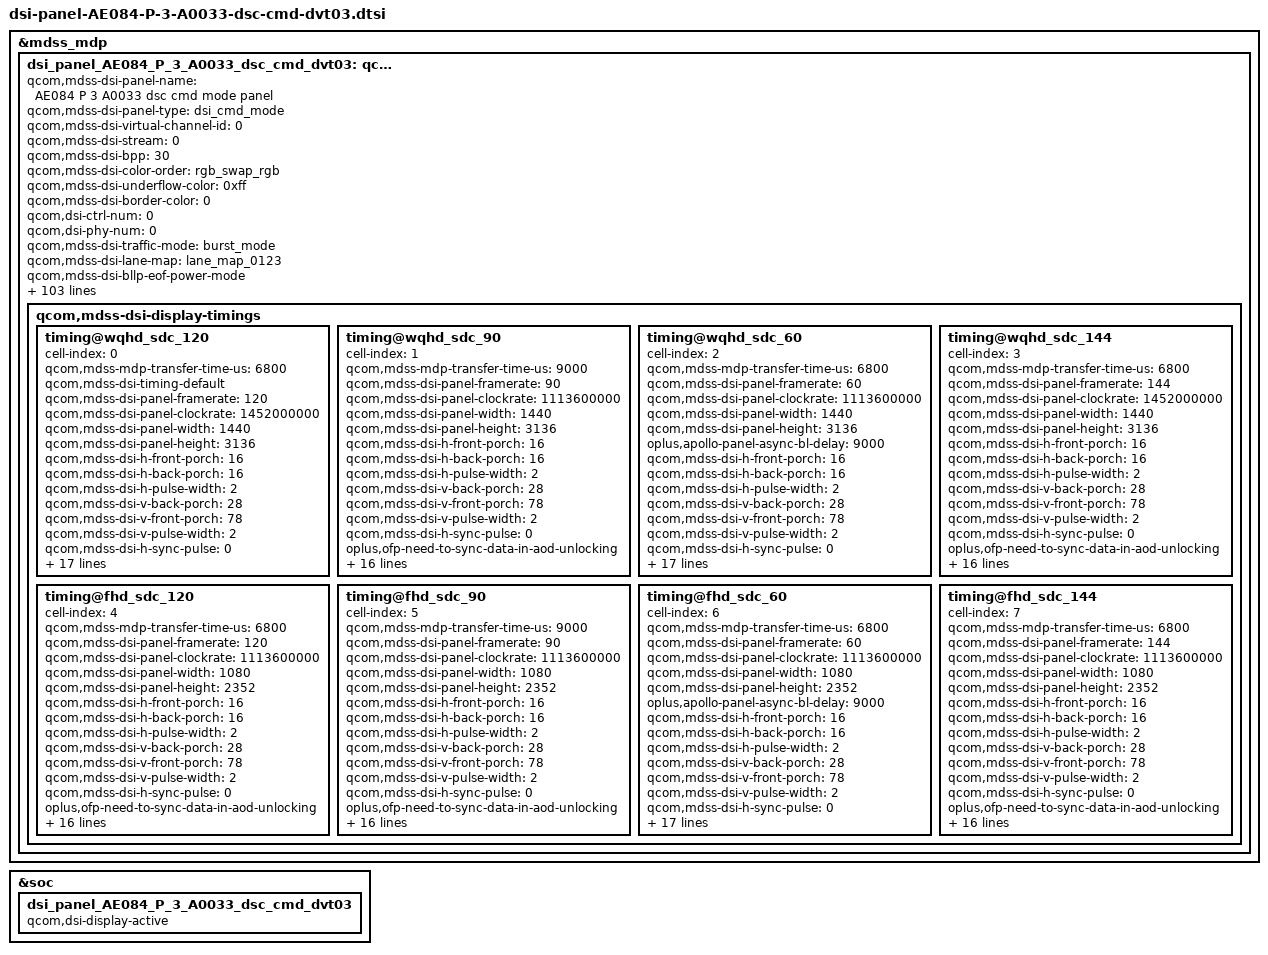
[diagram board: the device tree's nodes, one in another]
&mdss_mdp {
	dsi_panel_AE084_P_3_A0033_dsc_cmd_dvt03: qcom,mdss_dsi_panel_AE084_P_3_A0033_dsc_cmd_dvt03 {
		qcom,mdss-dsi-panel-name = "AE084 P 3 A0033 dsc cmd mode panel";
		qcom,mdss-dsi-panel-type = "dsi_cmd_mode";
		qcom,mdss-dsi-virtual-channel-id = <0>;
		qcom,mdss-dsi-stream = <0>;
		qcom,mdss-dsi-bpp = <30>;
		qcom,mdss-dsi-color-order = "rgb_swap_rgb";
		qcom,mdss-dsi-underflow-color = <0xff>;
		qcom,mdss-dsi-border-color = <0>;
		qcom,dsi-ctrl-num = <0>;
		qcom,dsi-phy-num = <0>;
		qcom,mdss-dsi-traffic-mode = "burst_mode";
		qcom,mdss-dsi-lane-map = "lane_map_0123";
		qcom,mdss-dsi-bllp-eof-power-mode;
		qcom,mdss-dsi-bllp-power-mode;
		qcom,mdss-dsi-lane-0-state;
		qcom,mdss-dsi-lane-1-state;
		qcom,mdss-dsi-lane-2-state;
		qcom,mdss-dsi-lane-3-state;
		qcom,mdss-dsi-dma-trigger = "trigger_sw";
		qcom,mdss-dsi-dma-schedule-line = <1>;
		qcom,mdss-dsi-dma-schedule-window = <10>;
		qcom,mdss-dsi-mdp-trigger = "none";
		qcom,mdss-dsi-reset-sequence = <1 2>, <0 5>, <1 12>;
		qcom,mdss-dsi-te-pin-select = <1>;
		qcom,mdss-dsi-te-dcs-command = <1>;
		qcom,mdss-pan-physical-width-dimension = <71>;
		qcom,mdss-pan-physical-height-dimension = <157>;
		qcom,mdss-dsi-init-delay-us = <1000>;
		qcom,mdss-dsi-te-check-enable;
		qcom,mdss-dsi-te-using-te-pin;
		qcom,mdss-dsi-lp11-init;
		qcom,mdss-dsi-wr-mem-start = <0x2c>;
		qcom,mdss-dsi-wr-mem-continue = <0x3c>;
		qcom,mdss-dsi-panel-jitter = <0x4 0x1>;
		qcom,mdss-bl-high2bit;
		qcom,mdss-dsi-panel-skip-pps-update;
  		/* HDR Setting */
		qcom,mdss-dsi-panel-hdr-enabled;
		qcom,mdss-dsi-panel-hdr-color-primaries = <15635 16450 34000 16000 13250 34500 7500 3000>;
		//update for [MPC15]android.mediapc.cts.PerformanceClassTest#testDisplayHdr pass
		//qcom,mdss-dsi-panel-peak-brightness = <5400000>;
		qcom,mdss-dsi-panel-peak-brightness = <20000000>;
		qcom,mdss-dsi-panel-average-brightness = <2000000>;
		qcom,mdss-dsi-panel-blackness-level = <4000>;

		qcom,mdss-dsi-display-timings {
			//2K
			timing@wqhd_sdc_120 {
				#include "dsi-panel-AE084-P-3-A0033-common.dtsi"
				#include "dsi-panel-AE084-P-3-A0033-common-effect.dtsi"
				cell-index = <0>;
				qcom,mdss-mdp-transfer-time-us = <6800>;
				qcom,mdss-dsi-timing-default;
				qcom,mdss-dsi-panel-framerate = <120>;
				qcom,mdss-dsi-panel-clockrate = <1452000000>;
				qcom,mdss-dsi-panel-width = <1440>;
				qcom,mdss-dsi-panel-height = <3136>;

				qcom,mdss-dsi-h-front-porch = <16>;
				qcom,mdss-dsi-h-back-porch = <16>;
				qcom,mdss-dsi-h-pulse-width = <2>;
				qcom,mdss-dsi-v-back-porch = <28>;
				qcom,mdss-dsi-v-front-porch = <78>;
				qcom,mdss-dsi-v-pulse-width = <2>;
				qcom,mdss-dsi-h-sync-pulse = <0>;

				oplus,ofp-need-to-sync-data-in-aod-unlocking;
				oplus,ofp-aod-off-insert-black-frame = <1>;
				oplus,ofp-aod-off-black-frame-total-time = <42>;
				oplus,ofp-need-to-separate-backlight;
				oplus,ofp-backlight-on-period = <1>;

				qcom,mdss-dsi-timing-switch-command = [
					// OD setting
					39 00 00 40 00 00 47 A9 02 08 E0 00 00 40 02 08 E1 01 02 20 04 02 08 E2 01 02 20 04 02 08 E1 0F 0F 16 02 08 E1 10 10 08 02 08 E2 0F 0F 1C 02 08 E2 10 10 0A 02 08 E1 1D 1E 0D 04 02 08 E2 1D 1E 12 06 02 08 E1 2B 2B 0A 02 08 E2 2B 2B 12
					39 00 00 40 00 00 45 A9 02 08 E1 39 3A 08 04 02 08 E2 39 3A 0A 04 02 08 E1 47 47 06 02 08 E2 47 47 06 02 08 E1 55 55 06 02 08 E2 55 55 06 02 08 E1 63 63 02 02 08 E2 63 63 02 02 08 E1 71 71 02 02 08 E2 71 71 02 02 08 E0 00 00 41
					//DSC setting unlock
					39 00 00 40 00 00 06 F0 55 AA 52 08 00
					39 00 00 40 00 00 02 6F 0D
					39 00 00 40 00 00 02 D8 40
					//DSC SET
					39 00 00 40 00 00 03 90 03 43
					39 00 00 40 00 00 13 91 AB A8 00 10 C2 00 02 68 01 BB 00 0A 06 67 04 C5 10 F0
					39 00 00 40 00 00 13 93 AB A8 00 10 C2 00 02 0E 01 84 00 07 06 67 06 5C 10 F0
					//Resolution binding
					39 00 00 40 00 00 05 2A 00 00 05 9F
					39 00 00 40 00 00 05 2B 00 00 0C 3F
					//DSC setting unlock
					39 00 00 40 00 00 06 F0 55 AA 52 08 00
					39 00 00 40 00 00 02 6F 0D
					39 00 00 40 00 00 02 D8 40
					//scale up off
					39 00 00 40 00 00 02 03 00
					39 00 00 40 00 00 02 8F 00
					//OSC Trim
					39 00 00 40 00 00 50 A9 02 01 C3 02 03 02 87 02 01 C3 08 08 87 02 01 C3 0B 0D 3F 39 4B 02 01 C3 0E 0F 3F 46 02 01 C3 10 10 DD 02 01 C3 11 13 3F 39 4B 02 01 C3 14 16 3F 46 DD 02 01 C3 23 25 3F 31 49 02 01 C3 26 27 3F 57 02 01 C3 28 28 DC 02 01 C3 29 2B 11 00 01
					//DSC setting lock
					39 00 00 40 00 00 06 F0 55 AA 52 08 00
					39 00 00 40 00 00 02 6F 0D
					39 00 00 40 00 00 02 D8 42
					//FPS setting 120Hz
					39 00 00 00 01 00 8F A9 01 00 2F 00 00 01 02 09 BD 00 00 05 02 08 B7 08 0F 00 C8 00 C8 02 58 02 58 02 08 B7 10 1F 03 E8 03 E8 03 E8 03 E8 05 DC 05 DC 07 D0 07 D0 02 08 B7 20 27 09 C4 09 C4 08 FC 08 FC 02 08 B7 28 2D 08 00 08 00 08 00 01 00 A2 00 20 07 02 01 DD 02 03 00 00 00 00 00 00 00 00 02 04 B5 02 03 00 03 00 00 00 00 00 00 01 00 9D 00 00 AA 01 00 8D 02 02 01 01 00 A3 00 0F 81 00 00 00 00 02 09 BD 00 00 04 00 00 00 00 00 01 00 A3 10 11 00 00
					39 00 00 00 00 00 06 F0 55 AA 52 08 FF
				];
				qcom,mdss-dsi-on-command = [
					//GPIO setting
					39 00 00 40 00 00 06 F0 55 AA 52 08 00
					39 00 00 40 00 00 05 BE 49 47 47 4A
					//APL BLK Setting
					39 00 00 40 00 00 06 F0 55 AA 52 08 00
					39 00 00 40 00 00 02 6F 78
					39 00 00 40 00 00 18 B0 11 00 2A 00 C2 01 DA 03 7C 05 B1 08 80 0B EE 0F FF 05 55 05 56 05 55
					//APL_BLK_R_NUM,APL_BLK_G_NUM,APL_BLK_B_NUM
					39 00 00 40 00 00 02 6F 6F
					39 00 00 40 00 00 07 B0 02 D0 05 A0 02 D0
					//Data Scale Ratio
					39 00 00 40 00 00 06 F0 55 AA 52 08 08
					39 00 00 40 00 00 17 C1 8E 33 EE 33 33 EE 33 33 EE 33 33 EE 33 33 BE 33 AC 9B AC 0D 0F FF
					39 00 00 40 00 00 02 6F 23
					39 00 00 40 00 00 15 C1 0E 33 EE 33 33 EE 33 33 EE 33 33 EE 33 33 BE 33 AC 9B AC 0D
					39 00 00 40 00 00 02 6F 37
					39 00 00 40 00 00 15 C1 0F FF FF FF FF FF FF FF FF FF FF FF FF FF DF FF 27 AD 27 33
					39 00 00 40 00 00 02 6F 4B
					39 00 00 40 00 00 15 C1 0E 33 EE 33 33 EE 33 33 EE 33 33 EE 33 33 BE 33 AC 9B AC 0D
					39 00 00 40 00 00 02 6F 5F
					39 00 00 40 00 00 15 C1 0F FF FF FF FF FF FF FF FF FF FF FF FF FF FF FF FF FF FF FF
					39 00 00 40 00 00 02 6F 73
					39 00 00 40 00 00 15 C1 0E 33 EE 33 33 EE 33 33 EE 33 33 EE 33 33 BE 33 AC 9B AC 0D
					//DS_DBV_TH
					39 00 00 40 00 00 11 BA 00 01 00 8A 00 8A 01 3C 01 3C 01 9D 01 9D 02 79
					39 00 00 40 00 00 02 6F 10
					39 00 00 40 00 00 11 BA 02 79 03 7D 03 7D 04 93 04 93 06 98 06 98 0A E2
					39 00 00 40 00 00 02 6F 20
					39 00 00 40 00 00 0D BA 0A E2 0D BB 0D BB 0F FE 0F FE 0F FF
					//APL_L/APL_H
					39 00 00 40 00 00 02 6F 20
					39 00 00 40 00 00 04 C1 0F 29 FF
					//HBM_LV0/1/2
					39 00 00 40 00 00 02 6F 1D
					39 00 00 40 00 00 04 C1 00 80 FF
					39 00 00 40 00 00 05 FF AA 55 A5 80
					//OSC Charge up 4uA
					39 00 00 40 00 00 02 6F 07
					39 00 00 40 00 00 02 F8 4D
					39 00 00 40 00 00 02 6F 23
					39 00 00 40 00 00 02 F8 4D
					//mtp_vgh_setting
					39 00 00 40 00 00 02 6F 04
					39 00 00 40 00 00 02 F2 1D
					//power on/off sequence
					39 00 00 40 00 00 02 6F 0A
					39 00 00 40 00 00 06 F6 70 70 70 70 70
					// stop_hclk_fskip & stop_hclk_vfp = 1
					39 00 00 40 00 00 05 FF AA 55 A5 81
					39 00 00 40 00 00 02 6F 0E
					39 00 00 40 00 00 02 F5 2B
					//bois clk,idle vfp clk off
					39 00 00 40 00 00 02 6F 0F
					39 00 00 40 00 00 02 F5 22
					// porch source setting
					39 00 00 40 00 00 02 6F 05
					39 00 00 40 00 00 03 FE 3C 3C
					//mipi timing optimize
					39 00 00 40 00 00 05 FF AA 55 A5 82
					39 00 00 40 00 00 02 6F 12
					39 00 00 40 00 00 03 F2 23 25
					//source status @ mtp status = hi-z
					39 00 00 40 00 00 06 F0 55 AA 52 08 00
					39 00 00 40 00 00 02 6F 04
					39 00 00 40 00 00 02 C2 32
					//Blue spot optimization
					39 00 00 40 00 00 06 F0 55 AA 52 08 00
					39 00 00 40 00 00 02 6F 31
					39 00 00 40 00 00 04 C0 00 22 00
					39 00 00 40 00 00 06 F0 55 AA 52 08 00
					39 00 00 40 00 00 02 6F 39
					39 00 00 40 00 00 04 C0 11 33 00
					//scaling up setting
					39 00 00 40 00 00 02 6F 0D
					39 00 00 40 00 00 02 D8 40
					39 00 00 40 00 00 02 C0 44
					//goa status @ mtp status = toggle
					39 00 00 40 00 00 06 F0 55 AA 52 08 01
					39 00 00 40 00 00 02 6F 08
					39 00 00 40 00 00 02 CA 00
					//keep command mode
					39 00 00 40 00 00 05 FF AA 55 A5 00
					39 00 00 40 00 00 06 F0 55 AA 52 00 00
					39 00 00 40 00 00 02 6F 02
					39 00 00 40 00 00 02 17 12
					39 00 00 40 00 00 02 35 08
					//BC Dimming OFF
					39 00 00 40 00 00 02 53 20
					//H_res = 1440 , V_res = 3136
					39 00 00 40 00 00 05 2a 00 00 05 9f
					39 00 00 40 00 00 05 2b 00 00 0C 3f
					//normal gma
					39 00 00 40 00 00 02 26 00
					//normal dbv
					39 00 00 40 00 00 03 51 00 00
					//idle dbv
					39 00 00 40 00 00 02 6F 04
					39 00 00 40 00 00 03 51 0D BB
					//LFCC LUT Table Sel
					39 00 00 40 00 00 02 68 00
					//md1,dpc temperature
					39 00 00 40 00 00 03 81 01 19
					//DSC setting unlock
					39 00 00 40 00 00 07 A9 02 00 D8 0D 0D 40
					//DSC SET
					39 00 00 40 00 00 03 90 03 43
					39 00 00 40 00 00 13 91 AB A8 00 10 C2 00 02 68 01 BB 00 0A 06 67 04 C5 10 F0
					39 00 00 00 00 00 13 93 AB A8 00 10 C2 00 02 0E 01 84 00 07 06 67 06 5C 10 F0
					//vdc & peak luminance
					39 00 00 40 00 00 03 5F 00 C0
					39 00 00 40 00 00 02 6F 07
					39 00 00 40 00 00 02 51 00
					//1nit rolling horizontal stripes
					39 00 00 40 00 00 06 F0 55 AA 52 08 00
					39 00 00 40 00 00 02 6F 62
					39 00 00 40 00 00 02 D5 0F
					39 00 00 40 00 00 02 6F 68
					39 00 00 40 00 00 02 D5 10
					//RND OFF
					39 00 00 40 00 00 06 F0 55 AA 52 08 07
					39 00 00 40 00 00 02 C0 06

					//OSC Trim
					39 00 00 40 00 00 06 F0 55 AA 52 08 01
					39 00 00 40 00 00 36 C3 99 29 02 87 19 00 29 00 87 19 00 3F 39 4B 3F 46 DD 3F 39 4B 3F 46 DD 3F 51 FE 3F 25 A9 3F 51 FE 3F 25 A9 3F 38 FC 3F 2C A8 11 00 00 00 00 00 77 00 AA 02 AA 02
					15 00 00 40 00 00 02 6F 04
					15 00 00 40 00 00 02 C3 19
					15 00 00 40 00 00 02 6F 09
					15 00 00 40 00 00 02 C3 19

					// OD setting
					39 00 00 40 00 00 06 F0 55 AA 52 08 08
					39 00 00 40 00 00 05 E0 41 01 01 01
					39 00 00 40 00 00 02 6F 06
					39 00 00 40 00 00 0E E0 80 00 21 32 43 54 65 76 87 98 99 99 99
					39 00 00 40 00 00 0F E1 03 20 04 0D 0E 0F 0F 10 12 14 14 17 1C 20
					39 00 00 40 00 00 0F E2 03 20 04 0A 0C 0E 10 12 17 1A 1E 1F 20 21
					39 00 00 40 00 00 0F E3 00 00 00 00 00 00 00 00 00 00 00 00 00 00
					39 00 00 40 00 00 02 6F 0E
					39 00 00 40 00 00 0F E1 03 16 08 0A 0B 0B 0C 0D 0E 0E 12 14 17 20
					39 00 00 40 00 00 02 6F 0E
					39 00 00 40 00 00 0F E2 03 1C 0A 0F 10 10 11 12 13 13 14 15 17 19
					39 00 00 40 00 00 02 6F 0E
					39 00 00 40 00 00 0F E3 00 00 00 00 00 00 00 00 00 00 00 00 00 00
					39 00 00 40 00 00 02 6F 1C
					39 00 00 40 00 00 0F E1 02 0D 04 0A 0A 0A 0A 0A 0A 0A 0B 0B 0D 0F
					39 00 00 40 00 00 02 6F 1C
					39 00 00 40 00 00 0F E2 02 12 06 06 06 07 08 08 08 08 08 0A 0C 0D
					39 00 00 40 00 00 02 6F 1C
					39 00 00 40 00 00 0F E3 00 00 00 04 04 04 04 04 07 07 08 08 0C 0F
					39 00 00 40 00 00 02 6F 2A
					39 00 00 40 00 00 0F E1 01 0A 04 05 05 06 07 08 08 0A 0B 0B 0E 13
					39 00 00 40 00 00 02 6F 2A
					39 00 00 40 00 00 0F E2 02 12 04 08 08 08 08 08 08 08 0A 0B 0D 11
					39 00 00 40 00 00 02 6F 2A
					39 00 00 40 00 00 0F E3 00 00 00 03 03 03 03 03  03 07 09 0B 0D 12
					39 00 00 40 00 00 02 6F 38
					39 00 00 40 00 00 0F E1 01 08 04 05 05 05 05 05 06 09 0A 0B 0D 11
					39 00 00 40 00 00 02 6F 38
					39 00 00 40 00 00 0F E2 01 0A 04 05 05 05 06 06 06 07 09 0B 0D 10
					39 00 00 40 00 00 02 6F 38
					39 00 00 40 00 00 0F E3 00 00 00 04 04 04 04 04 05 07 08 0A 0D 0F
					39 00 00 40 00 00 02 6F 46
					39 00 00 40 00 00 0F E1 01 06 03 05 05 05 05 05 06 08 09 0B 0C 0F
					39 00 00 40 00 00 02 6F 46
					39 00 00 40 00 00 0F E2 01 06 03 04 04 04 04 04 06 08 09 0A 0C 0F
					39 00 00 40 00 00 02 6F 46
					39 00 00 40 00 00 0F E3 00 00 00 03 03 03 03 03 06 08 09 0A 0C 10
					39 00 00 40 00 00 02 6F 54
					39 00 00 40 00 00 0F E1 01 06 03 04 04 04 04 04 06 08 09 0A 0B 0F
					39 00 00 40 00 00 02 6F 54
					39 00 00 40 00 00 0F E2 01 06 03 04 04 04 04 04 06 07 09 0A 0B 0E
					39 00 00 40 00 00 02 6F 54
					39 00 00 40 00 00 0F E3 00 00 00 02 02 03 03 04 05 07 09 0C 0E 12
					39 00 00 40 00 00 02 6F 62
					39 00 00 40 00 00 0F E1 01 02 02 03 03 04 04 04 06 07 08 0A 0C 0F
					39 00 00 40 00 00 02 6F 62
					39 00 00 40 00 00 0F E2 01 02 02 02 03 03 03 04 05 07 08 09 0A 0E
					39 00 00 40 00 00 02 6F 62
					39 00 00 40 00 00 0F E3 00 00 00 02 02 03 03 04 06 08 0A 0D 0E 12
					39 00 00 40 00 00 02 6F 70
					39 00 00 40 00 00 0F E1 01 02 02 02 03 03 03 04 05 07 09 0C 0D 11
					39 00 00 40 00 00 02 6F 70
					39 00 00 40 00 00 0F E2 01 02 02 02 03 03 03 04 05 07 09 0B 0C 0F
					39 00 00 40 00 00 02 6F 70
					39 00 00 40 00 00 0F E3 00 00 00 02 03 03 03 04 06 08 0B 0C 0C 0F

					//add uir config
					39 00 00 40 00 00 06 F0 55 AA 52 08 00
					15 00 00 40 00 00 02 6F 78
					39 00 00 40 00 00 18 B0 17 00 2A 00 C2 01 DA 03 7C 05 B1 08 80 0B EE 0F FF 05 55 05 56 05 55
					//APL_BLK_R_NUM,APL_BLK_G_NUM,APL_BLK_B_NUM
					15 00 00 40 00 00 02 6F 6F
					39 00 00 40 00 00 07 B0 02 D0 05 A0 02 D0
					//Data Scale Ratio
					39 00 00 40 00 00 06 F0 55 AA 52 08 08
					//DS_LV0_APL0
					39 00 00 40 00 00 17 C1 8E 33 EE 33 33 EE 33 33 EE 33 33 EE 33 33 BE 33 AC 9B AC 0D 0F FF
					//HBM_LV
					15 00 00 40 00 00 02 6F 1D
					39 00 00 40 00 00 03 C1 00 FF
					//APL_L/APL_H
					15 00 00 40 00 00 02 6F 20
					39 00 00 40 00 00 04 C1 0F 29 FF
					//DS_LV0_APL1
					15 00 00 40 00 00 02 6F 23
					39 00 00 40 00 00 15 C1 0E 33 EE 33 33 EE 33 33 EE 33 33 EE 33 33 BE 33 AC 9B AC 0D
					//DS_Lv1_Apl0
					15 00 00 40 00 00 02 6F 37
					39 00 00 40 00 00 15 C1 0F FF FF FF FF FF FF FF FF FF FF FF FF FF DF FF 27 AD 27 33
					//DS_Lv1_Apl1
					15 00 00 40 00 00 02 6F 4B
					39 00 00 40 00 00 15 C1 0E 33 EE 33 33 EE 33 33 EE 33 33 EE 33 33 BE 33 AC 9B AC 0D
					//DS_LV2_APL0
					15 00 00 40 00 00 02 6F 5F
					39 00 00 40 00 00 15 C1 0F FF FF FF FF FF FF FF FF FF FF FF FF FF FF FF FF FF FF FF
					//DS_LV2_APL1
					15 00 00 40 00 00 02 6F 73
					39 00 00 40 00 00 15 C1 0E 33 EE 33 33 EE 33 33 EE 33 33 EE 33 33 BE 33 AC 9B AC 0D
					//DS_DBV_TH
					39 00 00 40 00 00 11 BA 00 01 00 8A 00 8A 01 3C 01 3C 01 9D 01 9D 02 79
					15 00 00 40 00 00 02 6F 10
					39 00 00 40 00 00 11 BA 02 79 03 7D 03 7D 04 93 04 93 06 98 06 98 0A E2
					15 00 00 40 00 00 02 6F 20
					39 00 00 40 00 00 0D BA 0A E2 0D BB 0D BB 0F FE 0F FE 0F FF
					//GIR1.0
					15 00 00 40 00 00 02 6F 07
					15 00 00 00 00 00 02 51 00

					//Sleep out
					15 00 00 00 78 00 02 11 00
					//Display out
					15 00 00 00 00 00 02 29 00
					//scale up off
					39 00 00 40 00 00 05 2A 00 00 05 9F
					39 00 00 40 00 00 05 2B 00 00 0C 3F
					39 00 00 40 00 00 02 03 00
					39 00 00 40 00 00 02 8F 00
					//OSC Trim
					39 00 00 40 00 00 50 A9 02 01 C3 02 03 02 87 02 01 C3 08 08 87 02 01 C3 0B 0D 3F 39 4B 02 01 C3 0E 0F 3F 46 02 01 C3 10 10 DD 02 01 C3 11 13 3F 39 4B 02 01 C3 14 16 3F 46 DD 02 01 C3 23 25 3F 31 49 02 01 C3 26 27 3F 57 02 01 C3 28 28 DC 02 01 C3 29 2B 11 00 01
					//DSC setting lock
					39 00 00 40 00 00 07 A9 02 00 D8 0D 0D 42
					//FPS setting 120Hz
					39 00 00 00 01 00 8F A9 01 00 2F 00 00 01 02 09 BD 00 00 05 02 08 B7 08 0F 00 C8 00 C8 02 58 02 58 02 08 B7 10 1F 03 E8 03 E8 03 E8 03 E8 05 DC 05 DC 07 D0 07 D0 02 08 B7 20 27 09 C4 09 C4 08 FC 08 FC 02 08 B7 28 2D 08 00 08 00 08 00 01 00 A2 00 20 07 02 01 DD 02 03 00 00 00 00 00 00 00 00 02 04 B5 02 03 00 03 00 00 00 00 00 00 01 00 9D 00 00 AA 01 00 8D 02 02 01 01 00 A3 00 0F 81 00 00 00 00 02 09 BD 00 00 04 00 00 00 00 00 01 00 A3 10 11 00 00
				];

				qcom,lm-split = <720 720>;
				qcom,mdss-dsc-slice-height = <16>;
				qcom,mdss-dsc-slice-width = <720>;
			};
			timing@wqhd_sdc_90 {
				#include "dsi-panel-AE084-P-3-A0033-common.dtsi"
				#include "dsi-panel-AE084-P-3-A0033-common-effect.dtsi"
				cell-index = <1>;
				qcom,mdss-mdp-transfer-time-us = <9000>;
				qcom,mdss-dsi-panel-framerate = <90>;
				qcom,mdss-dsi-panel-clockrate = <1113600000>;
				qcom,mdss-dsi-panel-width = <1440>;
				qcom,mdss-dsi-panel-height = <3136>;

				qcom,mdss-dsi-h-front-porch = <16>;
				qcom,mdss-dsi-h-back-porch = <16>;
				qcom,mdss-dsi-h-pulse-width = <2>;
				qcom,mdss-dsi-v-back-porch = <28>;
				qcom,mdss-dsi-v-front-porch = <78>;
				qcom,mdss-dsi-v-pulse-width = <2>;
				qcom,mdss-dsi-h-sync-pulse = <0>;

				oplus,ofp-need-to-sync-data-in-aod-unlocking;
				oplus,ofp-aod-off-insert-black-frame = <1>;
				oplus,ofp-aod-off-black-frame-total-time = <42>;
				oplus,ofp-need-to-separate-backlight;
				oplus,ofp-backlight-on-period = <1>;

				qcom,mdss-dsi-timing-switch-command = [
					// OD setting
					39 00 00 40 00 00 47 A9 02 08 E0 00 00 40 02 08 E1 01 02 18 08 02 08 E2 01 02 1A 08 02 08 E1 0F 0F 1A 02 08 E1 10 10 08 02 08 E2 0F 0F 1A 02 08 E2 10 10 0B 02 08 E1 1D 1E 08 05 02 08 E2 1D 1E 0A 06 02 08 E1 2B 2B 09 02 08 E2 2B 2B 0B
					39 00 00 40 00 00 45 A9 02 08 E1 39 3A 04 04 02 08 E2 39 3A 04 04 02 08 E1 47 47 03 02 08 E2 47 47 03 02 08 E1 55 55 03 02 08 E2 55 55 03 02 08 E1 63 63 01 02 08 E2 63 63 01 02 08 E1 71 71 01 02 08 E2 71 71 01 02 08 E0 00 00 41
					//DSC setting unlock
					39 00 00 40 00 00 06 F0 55 AA 52 08 00
					39 00 00 40 00 00 02 6F 0D
					39 00 00 40 00 00 02 D8 40
					//DSC SET
					39 00 00 40 00 00 03 90 03 43
					39 00 00 40 00 00 13 91 AB A8 00 10 C2 00 02 68 01 BB 00 0A 06 67 04 C5 10 F0
					39 00 00 40 00 00 13 93 AB A8 00 10 C2 00 02 0E 01 84 00 07 06 67 06 5C 10 F0
					//Resolution binding
					39 00 00 40 00 00 05 2A 00 00 05 9F
					39 00 00 40 00 00 05 2B 00 00 0C 3F
					//DSC setting unlock
					39 00 00 40 00 00 06 F0 55 AA 52 08 00
					39 00 00 40 00 00 02 6F 0D
					39 00 00 40 00 00 02 D8 40
					//scale up off
					39 00 00 40 00 00 02 03 00
					39 00 00 40 00 00 02 8F 00
					//OSC Trim
					39 00 00 40 00 00 50 A9 02 01 C3 02 03 02 87 02 01 C3 08 08 87 02 01 C3 0B 0D 3F 39 4B 02 01 C3 0E 0F 3F 46 02 01 C3 10 10 DD 02 01 C3 11 13 3F 39 4B 02 01 C3 14 16 3F 46 DD 02 01 C3 23 25 3F 38 FC 02 01 C3 26 27 3F 2C 02 01 C3 28 28 A8 02 01 C3 29 2B 11 00 00
					//DSC setting lock
					39 00 00 40 00 00 06 F0 55 AA 52 08 00
					39 00 00 40 00 00 02 6F 0D
					39 00 00 40 00 00 02 D8 42
					//FPS setting 90Hz
					39 00 00 00 01 00 8F A9 01 00 2F 00 00 02 02 09 BD 00 00 05 02 08 B7 08 0F 00 C8 00 C8 02 58 02 58 02 08 B7 10 1F 03 E8 03 E8 03 E8 03 E8 05 DC 05 DC 07 D0 07 D0 02 08 B7 20 27 09 C4 09 C4 08 FC 08 FC 02 08 B7 28 2D 08 00 08 00 08 00 01 00 A2 00 20 07 02 01 DD 02 03 00 00 00 00 00 00 00 00 02 04 B5 02 03 00 09 00 00 00 00 00 00 01 00 9D 00 00 AA 01 00 8D 02 02 01 01 00 A3 00 0F 81 00 00 00 00 02 09 BD 00 00 04 00 00 00 00 00 01 00 A3 10 11 00 00
					39 00 00 00 00 00 06 F0 55 AA 52 08 FF
				];
				qcom,mdss-dsi-on-command = [
					//GPIO setting
					39 00 00 40 00 00 06 F0 55 AA 52 08 00
					39 00 00 40 00 00 05 BE 49 47 47 4A
					//APL BLK Setting
					39 00 00 40 00 00 06 F0 55 AA 52 08 00
					39 00 00 40 00 00 02 6F 78
					39 00 00 40 00 00 18 B0 11 00 2A 00 C2 01 DA 03 7C 05 B1 08 80 0B EE 0F FF 05 55 05 56 05 55
					//APL_BLK_R_NUM,APL_BLK_G_NUM,APL_BLK_B_NUM
					39 00 00 40 00 00 02 6F 6F
					39 00 00 40 00 00 07 B0 02 D0 05 A0 02 D0
					//Data Scale Ratio
					39 00 00 40 00 00 06 F0 55 AA 52 08 08
					39 00 00 40 00 00 17 C1 8E 33 EE 33 33 EE 33 33 EE 33 33 EE 33 33 BE 33 AC 9B AC 0D 0F FF
					39 00 00 40 00 00 02 6F 23
					39 00 00 40 00 00 15 C1 0E 33 EE 33 33 EE 33 33 EE 33 33 EE 33 33 BE 33 AC 9B AC 0D
					39 00 00 40 00 00 02 6F 37
					39 00 00 40 00 00 15 C1 0F FF FF FF FF FF FF FF FF FF FF FF FF FF DF FF 27 AD 27 33
					39 00 00 40 00 00 02 6F 4B
					39 00 00 40 00 00 15 C1 0E 33 EE 33 33 EE 33 33 EE 33 33 EE 33 33 BE 33 AC 9B AC 0D
					39 00 00 40 00 00 02 6F 5F
					39 00 00 40 00 00 15 C1 0F FF FF FF FF FF FF FF FF FF FF FF FF FF FF FF FF FF FF FF
					39 00 00 40 00 00 02 6F 73
					39 00 00 40 00 00 15 C1 0E 33 EE 33 33 EE 33 33 EE 33 33 EE 33 33 BE 33 AC 9B AC 0D
					//DS_DBV_TH
					39 00 00 40 00 00 11 BA 00 01 00 8A 00 8A 01 3C 01 3C 01 9D 01 9D 02 79
					39 00 00 40 00 00 02 6F 10
					39 00 00 40 00 00 11 BA 02 79 03 7D 03 7D 04 93 04 93 06 98 06 98 0A E2
					39 00 00 40 00 00 02 6F 20
					39 00 00 40 00 00 0D BA 0A E2 0D BB 0D BB 0F FE 0F FE 0F FF
					//APL_L/APL_H
					39 00 00 40 00 00 02 6F 20
					39 00 00 40 00 00 04 C1 0F 29 FF
					//HBM_LV0/1/2
					39 00 00 40 00 00 02 6F 1D
					39 00 00 40 00 00 04 C1 00 80 FF
					39 00 00 40 00 00 05 FF AA 55 A5 80
					//OSC Charge up 4uA
					39 00 00 40 00 00 02 6F 07
					39 00 00 40 00 00 02 F8 4D
					39 00 00 40 00 00 02 6F 23
					39 00 00 40 00 00 02 F8 4D
					//mtp_vgh_setting
					39 00 00 40 00 00 02 6F 04
					39 00 00 40 00 00 02 F2 1D
					//power on/off sequence
					39 00 00 40 00 00 02 6F 0A
					39 00 00 40 00 00 06 F6 70 70 70 70 70
					// stop_hclk_fskip & stop_hclk_vfp = 1
					39 00 00 40 00 00 05 FF AA 55 A5 81
					39 00 00 40 00 00 02 6F 0E
					39 00 00 40 00 00 02 F5 2B
					//bois clk,idle vfp clk off
					39 00 00 40 00 00 02 6F 0F
					39 00 00 40 00 00 02 F5 22
					// porch source setting
					39 00 00 40 00 00 02 6F 05
					39 00 00 40 00 00 03 FE 3C 3C
					//mipi timing optimize
					39 00 00 40 00 00 05 FF AA 55 A5 82
					39 00 00 40 00 00 02 6F 12
					39 00 00 40 00 00 03 F2 23 25
					//source status @ mtp status = hi-z
					39 00 00 40 00 00 06 F0 55 AA 52 08 00
					39 00 00 40 00 00 02 6F 04
					39 00 00 40 00 00 02 C2 32
					//Blue spot optimization
					39 00 00 40 00 00 06 F0 55 AA 52 08 00
					39 00 00 40 00 00 02 6F 31
					39 00 00 40 00 00 04 C0 00 22 00
					39 00 00 40 00 00 06 F0 55 AA 52 08 00
					39 00 00 40 00 00 02 6F 39
					39 00 00 40 00 00 04 C0 11 33 00
					//scaling up setting
					39 00 00 40 00 00 02 6F 0D
					39 00 00 40 00 00 02 D8 40
					39 00 00 40 00 00 02 C0 44
					//goa status @ mtp status = toggle
					39 00 00 40 00 00 06 F0 55 AA 52 08 01
					39 00 00 40 00 00 02 6F 08
					39 00 00 40 00 00 02 CA 00
					//keep command mode
					39 00 00 40 00 00 05 FF AA 55 A5 00
					39 00 00 40 00 00 06 F0 55 AA 52 00 00
					39 00 00 40 00 00 02 6F 02
					39 00 00 40 00 00 02 17 12
					39 00 00 40 00 00 02 35 08
					//BC Dimming OFF
					39 00 00 40 00 00 02 53 20
					//H_res = 1440 , V_res = 3136
					39 00 00 40 00 00 05 2a 00 00 05 9f
					39 00 00 40 00 00 05 2b 00 00 0C 3f
					//normal gma
					39 00 00 40 00 00 02 26 00
					//normal dbv
					39 00 00 40 00 00 03 51 00 00
					//idle dbv
					39 00 00 40 00 00 02 6F 04
					39 00 00 40 00 00 03 51 0D BB
					//LFCC LUT Table Sel
					39 00 00 40 00 00 02 68 00
					//md1,dpc temperature
					39 00 00 40 00 00 03 81 01 19
					//DSC setting unlock
					39 00 00 40 00 00 07 A9 02 00 D8 0D 0D 40
					//DSC SET
					39 00 00 40 00 00 03 90 03 43
					39 00 00 40 00 00 13 91 AB A8 00 10 C2 00 02 68 01 BB 00 0A 06 67 04 C5 10 F0
					39 00 00 00 00 00 13 93 AB A8 00 10 C2 00 02 0E 01 84 00 07 06 67 06 5C 10 F0
					//vdc & peak luminance
					39 00 00 40 00 00 03 5F 00 C0
					39 00 00 40 00 00 02 6F 07
					39 00 00 40 00 00 02 51 00
					//1nit rolling horizontal stripes
					39 00 00 40 00 00 06 F0 55 AA 52 08 00
					39 00 00 40 00 00 02 6F 62
					39 00 00 40 00 00 02 D5 0F
					39 00 00 40 00 00 02 6F 68
					39 00 00 40 00 00 02 D5 10
					//RND OFF
					39 00 00 40 00 00 06 F0 55 AA 52 08 07
					39 00 00 40 00 00 02 C0 06

					//OSC Trim
					39 00 00 40 00 00 06 F0 55 AA 52 08 01
					39 00 00 40 00 00 36 C3 99 29 02 87 19 00 29 00 87 19 00 3F 39 4B 3F 46 DD 3F 39 4B 3F 46 DD 3F 51 FE 3F 25 A9 3F 51 FE 3F 25 A9 3F 38 FC 3F 2C A8 11 00 00 00 00 00 77 00 AA 02 AA 02
					15 00 00 40 00 00 02 6F 04
					15 00 00 40 00 00 02 C3 19
					15 00 00 40 00 00 02 6F 09
					15 00 00 40 00 00 02 C3 19

					// OD setting
					39 00 00 40 00 00 06 F0 55 AA 52 08 08
					39 00 00 40 00 00 05 E0 41 01 01 01
					39 00 00 40 00 00 02 6F 06
					39 00 00 40 00 00 0E E0 80 00 21 32 43 54 65 76 87 98 99 99 99
					39 00 00 40 00 00 0F E1 03 18 08 0D 0E 0F 0F 10 12 14 14 17 1C 20
					39 00 00 40 00 00 0F E2 03 1A 08 0A 0C 0E 10 12 17 1A 1E 1F 20 21
					39 00 00 40 00 00 0F E3 00 00 00 00 00 00 00 00 00 00 00 00 00 00
					39 00 00 40 00 00 02 6F 0E
					39 00 00 40 00 00 0F E1 03 18 08 0A 0B 0B 0C 0D 0E 0E 12 14 17 20
					39 00 00 40 00 00 02 6F 0E
					39 00 00 40 00 00 0F E2 03 1A 0B 0F 10 10 11 12 13 13 14 15 17 19
					39 00 00 40 00 00 02 6F 0E
					39 00 00 40 00 00 0F E3 00 00 00 00 00 00 00 00 00 00 00 00 00 00
					39 00 00 40 00 00 02 6F 1C
					39 00 00 40 00 00 0F E1 02 08 05 0A 0A 0A 0A 0A 0A 0A 0B 0B 0D 0F
					39 00 00 40 00 00 02 6F 1C
					39 00 00 40 00 00 0F E2 02 0A 06 06 06 07 08 08 08 08 08 0A 0C 0D
					39 00 00 40 00 00 02 6F 1C
					39 00 00 40 00 00 0F E3 00 00 00 04 04 04 04 04 07 07 08 08 0C 0F
					39 00 00 40 00 00 02 6F 2A
					39 00 00 40 00 00 0F E1 01 09 04 05 05 06 07 08 08 0A 0B 0B 0E 13
					39 00 00 40 00 00 02 6F 2A
					39 00 00 40 00 00 0F E2 02 0B 04 08 08 08 08 08 08 08 0A 0B 0D 11
					39 00 00 40 00 00 02 6F 2A
					39 00 00 40 00 00 0F E3 00 00 00 03 03 03 03 03  03 07 09 0B 0D 12
					39 00 00 40 00 00 02 6F 38
					39 00 00 40 00 00 0F E1 01 04 04 05 05 05 05 05 06 09 0A 0B 0D 11
					39 00 00 40 00 00 02 6F 38
					39 00 00 40 00 00 0F E2 01 04 04 05 05 05 06 06 06 07 09 0B 0D 10
					39 00 00 40 00 00 02 6F 38
					39 00 00 40 00 00 0F E3 00 00 00 04 04 04 04 04 05 07 08 0A 0D 0F
					39 00 00 40 00 00 02 6F 46
					39 00 00 40 00 00 0F E1 01 03 03 05 05 05 05 05 06 08 09 0B 0C 0F
					39 00 00 40 00 00 02 6F 46
					39 00 00 40 00 00 0F E2 01 03 03 04 04 04 04 04 06 08 09 0A 0C 0F
					39 00 00 40 00 00 02 6F 46
					39 00 00 40 00 00 0F E3 00 00 00 03 03 03 03 03 06 08 09 0A 0C 10
					39 00 00 40 00 00 02 6F 54
					39 00 00 40 00 00 0F E1 01 03 03 04 04 04 04 04 06 08 09 0A 0B 0F
					39 00 00 40 00 00 02 6F 54
					39 00 00 40 00 00 0F E2 01 03 03 04 04 04 04 04 06 07 09 0A 0B 0E
					39 00 00 40 00 00 02 6F 54
					39 00 00 40 00 00 0F E3 00 00 00 02 02 03 03 04 05 07 09 0C 0E 12
					39 00 00 40 00 00 02 6F 62
					39 00 00 40 00 00 0F E1 01 01 02 03 03 04 04 04 06 07 08 0A 0C 0F
					39 00 00 40 00 00 02 6F 62
					39 00 00 40 00 00 0F E2 01 01 02 02 03 03 03 04 05 07 08 09 0A 0E
					39 00 00 40 00 00 02 6F 62
					39 00 00 40 00 00 0F E3 00 00 00 02 02 03 03 04 06 08 0A 0D 0E 12
					39 00 00 40 00 00 02 6F 70
					39 00 00 40 00 00 0F E1 01 01 02 02 03 03 03 04 05 07 09 0C 0D 11
					39 00 00 40 00 00 02 6F 70
					39 00 00 40 00 00 0F E2 01 01 02 02 03 03 03 04 05 07 09 0B 0C 0F
					39 00 00 40 00 00 02 6F 70
					39 00 00 40 00 00 0F E3 00 00 00 02 03 03 03 04 06 08 0B 0C 0C 0F

					//add uir config
					39 00 00 40 00 00 06 F0 55 AA 52 08 00
					15 00 00 40 00 00 02 6F 78
					39 00 00 40 00 00 18 B0 17 00 2A 00 C2 01 DA 03 7C 05 B1 08 80 0B EE 0F FF 05 55 05 56 05 55
					//APL_BLK_R_NUM,APL_BLK_G_NUM,APL_BLK_B_NUM
					15 00 00 40 00 00 02 6F 6F
					39 00 00 40 00 00 07 B0 02 D0 05 A0 02 D0
					//Data Scale Ratio
					39 00 00 40 00 00 06 F0 55 AA 52 08 08
					//DS_LV0_APL0
					39 00 00 40 00 00 17 C1 8E 33 EE 33 33 EE 33 33 EE 33 33 EE 33 33 BE 33 AC 9B AC 0D 0F FF
					//HBM_LV
					15 00 00 40 00 00 02 6F 1D
					39 00 00 40 00 00 03 C1 00 FF
					//APL_L/APL_H
					15 00 00 40 00 00 02 6F 20
					39 00 00 40 00 00 04 C1 0F 29 FF
					//DS_LV0_APL1
					15 00 00 40 00 00 02 6F 23
					39 00 00 40 00 00 15 C1 0E 33 EE 33 33 EE 33 33 EE 33 33 EE 33 33 BE 33 AC 9B AC 0D
					//DS_Lv1_Apl0
					15 00 00 40 00 00 02 6F 37
					39 00 00 40 00 00 15 C1 0F FF FF FF FF FF FF FF FF FF FF FF FF FF DF FF 27 AD 27 33
					//DS_Lv1_Apl1
					15 00 00 40 00 00 02 6F 4B
					39 00 00 40 00 00 15 C1 0E 33 EE 33 33 EE 33 33 EE 33 33 EE 33 33 BE 33 AC 9B AC 0D
					//DS_LV2_APL0
					15 00 00 40 00 00 02 6F 5F
					39 00 00 40 00 00 15 C1 0F FF FF FF FF FF FF FF FF FF FF FF FF FF FF FF FF FF FF FF
					//DS_LV2_APL1
					15 00 00 40 00 00 02 6F 73
					39 00 00 40 00 00 15 C1 0E 33 EE 33 33 EE 33 33 EE 33 33 EE 33 33 BE 33 AC 9B AC 0D
					//DS_DBV_TH
					39 00 00 40 00 00 11 BA 00 01 00 8A 00 8A 01 3C 01 3C 01 9D 01 9D 02 79
					15 00 00 40 00 00 02 6F 10
					39 00 00 40 00 00 11 BA 02 79 03 7D 03 7D 04 93 04 93 06 98 06 98 0A E2
					15 00 00 40 00 00 02 6F 20
					39 00 00 40 00 00 0D BA 0A E2 0D BB 0D BB 0F FE 0F FE 0F FF
					//GIR1.0
					15 00 00 40 00 00 02 6F 07
					15 00 00 00 00 00 02 51 00

					//Sleep out
					15 00 00 00 78 00 02 11 00
					//Display out
					15 00 00 00 00 00 02 29 00
					//scale up off
					39 00 00 40 00 00 05 2A 00 00 05 9F
					39 00 00 40 00 00 05 2B 00 00 0C 3F
					39 00 00 40 00 00 02 03 00
					39 00 00 40 00 00 02 8F 00
					//OSC Trim
					39 00 00 40 00 00 50 A9 02 01 C3 02 03 02 87 02 01 C3 08 08 87 02 01 C3 0B 0D 3F 39 4B 02 01 C3 0E 0F 3F 46 02 01 C3 10 10 DD 02 01 C3 11 13 3F 39 4B 02 01 C3 14 16 3F 46 DD 02 01 C3 23 25 3F 38 FC 02 01 C3 26 27 3F 2C 02 01 C3 28 28 A8 02 01 C3 29 2B 11 00 00
					//DSC setting lock
					39 00 00 40 00 00 07 A9 02 00 D8 0D 0D 42
					//FPS setting 90Hz
					39 00 00 00 01 00 8F A9 01 00 2F 00 00 02 02 09 BD 00 00 05 02 08 B7 08 0F 00 C8 00 C8 02 58 02 58 02 08 B7 10 1F 03 E8 03 E8 03 E8 03 E8 05 DC 05 DC 07 D0 07 D0 02 08 B7 20 27 09 C4 09 C4 08 FC 08 FC 02 08 B7 28 2D 08 00 08 00 08 00 01 00 A2 00 20 07 02 01 DD 02 03 00 00 00 00 00 00 00 00 02 04 B5 02 03 00 09 00 00 00 00 00 00 01 00 9D 00 00 AA 01 00 8D 02 02 01 01 00 A3 00 0F 81 00 00 00 00 02 09 BD 00 00 04 00 00 00 00 00 01 00 A3 10 11 00 00
				];

				qcom,lm-split = <720 720>;
				qcom,mdss-dsc-slice-height = <16>;
				qcom,mdss-dsc-slice-width = <720>;
			};
			timing@wqhd_sdc_60 {
				#include "dsi-panel-AE084-P-3-A0033-common.dtsi"
				#include "dsi-panel-AE084-P-3-A0033-common-effect.dtsi"
				cell-index = <2>;
				qcom,mdss-mdp-transfer-time-us = <6800>;
				qcom,mdss-dsi-panel-framerate = <60>;
				qcom,mdss-dsi-panel-clockrate = <1113600000>;
				qcom,mdss-dsi-panel-width = <1440>;
				qcom,mdss-dsi-panel-height = <3136>;
				oplus,apollo-panel-async-bl-delay = <9000>;

				qcom,mdss-dsi-h-front-porch = <16>;
				qcom,mdss-dsi-h-back-porch = <16>;
				qcom,mdss-dsi-h-pulse-width = <2>;
				qcom,mdss-dsi-v-back-porch = <28>;
				qcom,mdss-dsi-v-front-porch = <78>;
				qcom,mdss-dsi-v-pulse-width = <2>;
				qcom,mdss-dsi-h-sync-pulse = <0>;

				oplus,ofp-need-to-sync-data-in-aod-unlocking;
				oplus,ofp-aod-off-insert-black-frame = <1>;
				oplus,ofp-aod-off-black-frame-total-time = <42>;
				oplus,ofp-need-to-separate-backlight;
				oplus,ofp-backlight-on-period = <1>;

				qcom,mdss-dsi-timing-switch-command = [
					// OD setting
					39 00 00 40 00 00 47 A9 02 08 E0 00 00 40 02 08 E1 01 02 12 08 02 08 E2 01 02 12 06 02 08 E1 0F 0F 0A 02 08 E1 10 10 04 02 08 E2 0F 0F 0A 02 08 E2 10 10 04 02 08 E1 1D 1E 06 04 02 08 E2 1D 1E 08 06 02 08 E1 2B 2B 04 02 08 E2 2B 2B 06
					39 00 00 40 00 00 45 A9 02 08 E1 39 3A 03 03 02 08 E2 39 3A 04 03 02 08 E1 47 47 02 02 08 E2 47 47 02 02 08 E1 55 55 02 02 08 E2 55 55 02 02 08 E1 63 63 01 02 08 E2 63 63 01 02 08 E1 71 71 01 02 08 E2 71 71 01 02 08 E0 00 00 41
					//DSC setting unlock
					39 00 00 40 00 00 06 F0 55 AA 52 08 00
					39 00 00 40 00 00 02 6F 0D
					39 00 00 40 00 00 02 D8 40
					//DSC SET
					39 00 00 40 00 00 03 90 03 43
					39 00 00 40 00 00 13 91 AB A8 00 10 C2 00 02 68 01 BB 00 0A 06 67 04 C5 10 F0
					39 00 00 40 00 00 13 93 AB A8 00 10 C2 00 02 0E 01 84 00 07 06 67 06 5C 10 F0
					//Resolution binding
					39 00 00 40 00 00 05 2A 00 00 05 9F
					39 00 00 40 00 00 05 2B 00 00 0C 3F
					//DSC setting unlock
					39 00 00 40 00 00 06 F0 55 AA 52 08 00
					39 00 00 40 00 00 02 6F 0D
					39 00 00 40 00 00 02 D8 40
					//scale up off
					39 00 00 40 00 00 02 03 00
					39 00 00 40 00 00 02 8F 00
					//OSC Trim
					39 00 00 40 00 00 50 A9 02 01 C3 02 03 02 87 02 01 C3 08 08 87 02 01 C3 0B 0D 3F 39 4B 02 01 C3 0E 0F 3F 46 02 01 C3 10 10 DD 02 01 C3 11 13 3F 39 4B 02 01 C3 14 16 3F 46 DD 02 01 C3 23 25 3F 38 FC 02 01 C3 26 27 3F 2C 02 01 C3 28 28 A8 02 01 C3 29 2B 11 00 00
					//DSC setting lock
					39 00 00 40 00 00 06 F0 55 AA 52 08 00
					39 00 00 40 00 00 02 6F 0D
					39 00 00 40 00 00 02 D8 42
					//FPS setting 60Hz
					39 00 00 00 01 00 8F A9 01 00 2F 00 00 03 02 09 BD 00 00 05 02 08 B7 08 0F 00 C8 00 C8 02 58 02 58 02 08 B7 10 1F 03 E8 03 E8 03 E8 03 E8 05 DC 05 DC 07 D0 07 D0 02 08 B7 20 27 09 C4 09 C4 08 FC 08 FC 02 08 B7 28 2D 08 00 08 00 08 00 01 00 A2 00 20 07 02 01 DD 02 03 00 00 00 00 00 00 00 00 02 04 B5 02 03 00 03 00 00 00 00 00 00 01 00 9D 00 00 AA 01 00 8D 02 02 01 01 00 A3 00 0F 81 00 00 00 00 02 09 BD 00 00 04 00 00 00 00 00 01 00 A3 10 11 00 00
					39 00 00 00 00 00 06 F0 55 AA 52 08 FF
				];
				qcom,mdss-dsi-on-command = [
					//GPIO setting
					39 00 00 40 00 00 06 F0 55 AA 52 08 00
					39 00 00 40 00 00 05 BE 49 47 47 4A
					//APL BLK Setting
					39 00 00 40 00 00 06 F0 55 AA 52 08 00
					39 00 00 40 00 00 02 6F 78
					39 00 00 40 00 00 18 B0 11 00 2A 00 C2 01 DA 03 7C 05 B1 08 80 0B EE 0F FF 05 55 05 56 05 55
					//APL_BLK_R_NUM,APL_BLK_G_NUM,APL_BLK_B_NUM
					39 00 00 40 00 00 02 6F 6F
					39 00 00 40 00 00 07 B0 02 D0 05 A0 02 D0
					//Data Scale Ratio
					39 00 00 40 00 00 06 F0 55 AA 52 08 08
					39 00 00 40 00 00 17 C1 8E 33 EE 33 33 EE 33 33 EE 33 33 EE 33 33 BE 33 AC 9B AC 0D 0F FF
					39 00 00 40 00 00 02 6F 23
					39 00 00 40 00 00 15 C1 0E 33 EE 33 33 EE 33 33 EE 33 33 EE 33 33 BE 33 AC 9B AC 0D
					39 00 00 40 00 00 02 6F 37
					39 00 00 40 00 00 15 C1 0F FF FF FF FF FF FF FF FF FF FF FF FF FF DF FF 27 AD 27 33
					39 00 00 40 00 00 02 6F 4B
					39 00 00 40 00 00 15 C1 0E 33 EE 33 33 EE 33 33 EE 33 33 EE 33 33 BE 33 AC 9B AC 0D
					39 00 00 40 00 00 02 6F 5F
					39 00 00 40 00 00 15 C1 0F FF FF FF FF FF FF FF FF FF FF FF FF FF FF FF FF FF FF FF
					39 00 00 40 00 00 02 6F 73
					39 00 00 40 00 00 15 C1 0E 33 EE 33 33 EE 33 33 EE 33 33 EE 33 33 BE 33 AC 9B AC 0D
					//DS_DBV_TH
					39 00 00 40 00 00 11 BA 00 01 00 8A 00 8A 01 3C 01 3C 01 9D 01 9D 02 79
					39 00 00 40 00 00 02 6F 10
					39 00 00 40 00 00 11 BA 02 79 03 7D 03 7D 04 93 04 93 06 98 06 98 0A E2
					39 00 00 40 00 00 02 6F 20
					39 00 00 40 00 00 0D BA 0A E2 0D BB 0D BB 0F FE 0F FE 0F FF
					//APL_L/APL_H
					39 00 00 40 00 00 02 6F 20
					39 00 00 40 00 00 04 C1 0F 29 FF
					//HBM_LV0/1/2
					39 00 00 40 00 00 02 6F 1D
					39 00 00 40 00 00 04 C1 00 80 FF
					39 00 00 40 00 00 05 FF AA 55 A5 80
					//OSC Charge up 4uA
					39 00 00 40 00 00 02 6F 07
					39 00 00 40 00 00 02 F8 4D
					39 00 00 40 00 00 02 6F 23
					39 00 00 40 00 00 02 F8 4D
					//mtp_vgh_setting
					39 00 00 40 00 00 02 6F 04
					39 00 00 40 00 00 02 F2 1D
					//power on/off sequence
					39 00 00 40 00 00 02 6F 0A
					39 00 00 40 00 00 06 F6 70 70 70 70 70
					// stop_hclk_fskip & stop_hclk_vfp = 1
					39 00 00 40 00 00 05 FF AA 55 A5 81
					39 00 00 40 00 00 02 6F 0E
					39 00 00 40 00 00 02 F5 2B
					//bois clk,idle vfp clk off
					39 00 00 40 00 00 02 6F 0F
					39 00 00 40 00 00 02 F5 22
					// porch source setting
					39 00 00 40 00 00 02 6F 05
					39 00 00 40 00 00 03 FE 3C 3C
					//mipi timing optimize
					39 00 00 40 00 00 05 FF AA 55 A5 82
					39 00 00 40 00 00 02 6F 12
					39 00 00 40 00 00 03 F2 23 25
					//source status @ mtp status = hi-z
					39 00 00 40 00 00 06 F0 55 AA 52 08 00
					39 00 00 40 00 00 02 6F 04
					39 00 00 40 00 00 02 C2 32
					//Blue spot optimization
					39 00 00 40 00 00 06 F0 55 AA 52 08 00
					39 00 00 40 00 00 02 6F 31
					39 00 00 40 00 00 04 C0 00 22 00
					39 00 00 40 00 00 06 F0 55 AA 52 08 00
					39 00 00 40 00 00 02 6F 39
					39 00 00 40 00 00 04 C0 11 33 00
					//scaling up setting
					39 00 00 40 00 00 02 6F 0D
					39 00 00 40 00 00 02 D8 40
					39 00 00 40 00 00 02 C0 44
					//goa status @ mtp status = toggle
					39 00 00 40 00 00 06 F0 55 AA 52 08 01
					39 00 00 40 00 00 02 6F 08
					39 00 00 40 00 00 02 CA 00
					//keep command mode
					39 00 00 40 00 00 05 FF AA 55 A5 00
					39 00 00 40 00 00 06 F0 55 AA 52 00 00
					39 00 00 40 00 00 02 6F 02
					39 00 00 40 00 00 02 17 12
					39 00 00 40 00 00 02 35 08
					//BC Dimming OFF
					39 00 00 40 00 00 02 53 20
					//H_res = 1440 , V_res = 3136
					39 00 00 40 00 00 05 2a 00 00 05 9f
					39 00 00 40 00 00 05 2b 00 00 0C 3f
					//normal gma
					39 00 00 40 00 00 02 26 00
					//normal dbv
					39 00 00 40 00 00 03 51 00 00
					//idle dbv
					39 00 00 40 00 00 02 6F 04
					39 00 00 40 00 00 03 51 0D BB
					//LFCC LUT Table Sel
					39 00 00 40 00 00 02 68 00
					//md1,dpc temperature
					39 00 00 40 00 00 03 81 01 19
					//DSC setting unlock
					39 00 00 40 00 00 07 A9 02 00 D8 0D 0D 40
					//DSC SET
					39 00 00 40 00 00 03 90 03 43
					39 00 00 40 00 00 13 91 AB A8 00 10 C2 00 02 68 01 BB 00 0A 06 67 04 C5 10 F0
					39 00 00 00 00 00 13 93 AB A8 00 10 C2 00 02 0E 01 84 00 07 06 67 06 5C 10 F0
					//vdc & peak luminance
					39 00 00 40 00 00 03 5F 00 C0
					39 00 00 40 00 00 02 6F 07
					39 00 00 40 00 00 02 51 00
					//1nit rolling horizontal stripes
					39 00 00 40 00 00 06 F0 55 AA 52 08 00
					39 00 00 40 00 00 02 6F 62
					39 00 00 40 00 00 02 D5 0F
					39 00 00 40 00 00 02 6F 68
					39 00 00 40 00 00 02 D5 10
					//RND OFF
					39 00 00 40 00 00 06 F0 55 AA 52 08 07
					39 00 00 40 00 00 02 C0 06

					//OSC Trim
					39 00 00 40 00 00 06 F0 55 AA 52 08 01
					39 00 00 40 00 00 36 C3 99 29 02 87 19 00 29 00 87 19 00 3F 39 4B 3F 46 DD 3F 39 4B 3F 46 DD 3F 51 FE 3F 25 A9 3F 51 FE 3F 25 A9 3F 38 FC 3F 2C A8 11 00 00 00 00 00 77 00 AA 02 AA 02
					15 00 00 40 00 00 02 6F 04
					15 00 00 40 00 00 02 C3 19
					15 00 00 40 00 00 02 6F 09
					15 00 00 40 00 00 02 C3 19

					// OD setting
					39 00 00 40 00 00 06 F0 55 AA 52 08 08
					39 00 00 40 00 00 05 E0 41 01 01 01
					39 00 00 40 00 00 02 6F 06
					39 00 00 40 00 00 0E E0 80 00 21 32 43 54 65 76 87 98 99 99 99
					39 00 00 40 00 00 0F E1 03 12 08 0D 0E 0F 0F 10 12 14 14 17 1C 20
					39 00 00 40 00 00 0F E2 03 12 06 0A 0C 0E 10 12 17 1A 1E 1F 20 21
					39 00 00 40 00 00 0F E3 00 00 00 00 00 00 00 00 00 00 00 00 00 00
					39 00 00 40 00 00 02 6F 0E
					39 00 00 40 00 00 0F E1 03 0A 04 0A 0B 0B 0C 0D 0E 0E 12 14 17 20
					39 00 00 40 00 00 02 6F 0E
					39 00 00 40 00 00 0F E2 03 0A 04 0F 10 10 11 12 13 13 14 15 17 19
					39 00 00 40 00 00 02 6F 0E
					39 00 00 40 00 00 0F E3 00 00 00 00 00 00 00 00 00 00 00 00 00 00
					39 00 00 40 00 00 02 6F 1C
					39 00 00 40 00 00 0F E1 02 06 04 0A 0A 0A 0A 0A 0A 0A 0B 0B 0D 0F
					39 00 00 40 00 00 02 6F 1C
					39 00 00 40 00 00 0F E2 02 08 06 06 06 07 08 08 08 08 08 0A 0C 0D
					39 00 00 40 00 00 02 6F 1C
					39 00 00 40 00 00 0F E3 00 00 00 04 04 04 04 04 07 07 08 08 0C 0F
					39 00 00 40 00 00 02 6F 2A
					39 00 00 40 00 00 0F E1 01 04 04 05 05 06 07 08 08 0A 0B 0B 0E 13
					39 00 00 40 00 00 02 6F 2A
					39 00 00 40 00 00 0F E2 02 06 04 08 08 08 08 08 08 08 0A 0B 0D 11
					39 00 00 40 00 00 02 6F 2A
					39 00 00 40 00 00 0F E3 00 00 00 03 03 03 03 03  03 07 09 0B 0D 12
					39 00 00 40 00 00 02 6F 38
					39 00 00 40 00 00 0F E1 01 03 03 05 05 05 05 05 06 09 0A 0B 0D 11
					39 00 00 40 00 00 02 6F 38
					39 00 00 40 00 00 0F E2 01 04 03 05 05 05 06 06 06 07 09 0B 0D 10
					39 00 00 40 00 00 02 6F 38
					39 00 00 40 00 00 0F E3 00 00 00 04 04 04 04 04 05 07 08 0A 0D 0F
					39 00 00 40 00 00 02 6F 46
					39 00 00 40 00 00 0F E1 01 02 03 05 05 05 05 05 06 08 09 0B 0C 0F
					39 00 00 40 00 00 02 6F 46
					39 00 00 40 00 00 0F E2 01 02 03 04 04 04 04 04 06 08 09 0A 0C 0F
					39 00 00 40 00 00 02 6F 46
					39 00 00 40 00 00 0F E3 00 00 00 03 03 03 03 03 06 08 09 0A 0C 10
					39 00 00 40 00 00 02 6F 54
					39 00 00 40 00 00 0F E1 01 02 03 04 04 04 04 04 06 08 09 0A 0B 0F
					39 00 00 40 00 00 02 6F 54
					39 00 00 40 00 00 0F E2 01 02 03 04 04 04 04 04 06 07 09 0A 0B 0E
					39 00 00 40 00 00 02 6F 54
					39 00 00 40 00 00 0F E3 00 00 00 02 02 03 03 04 05 07 09 0C 0E 12
					39 00 00 40 00 00 02 6F 62
					39 00 00 40 00 00 0F E1 01 01 02 03 03 04 04 04 06 07 08 0A 0C 0F
					39 00 00 40 00 00 02 6F 62
					39 00 00 40 00 00 0F E2 01 01 02 02 03 03 03 04 05 07 08 09 0A 0E
					39 00 00 40 00 00 02 6F 62
					39 00 00 40 00 00 0F E3 00 00 00 02 02 03 03 04 06 08 0A 0D 0E 12
					39 00 00 40 00 00 02 6F 70
					39 00 00 40 00 00 0F E1 01 01 02 02 03 03 03 04 05 07 09 0C 0D 11
					39 00 00 40 00 00 02 6F 70
					39 00 00 40 00 00 0F E2 01 01 02 02 03 03 03 04 05 07 09 0B 0C 0F
					39 00 00 40 00 00 02 6F 70
					39 00 00 40 00 00 0F E3 00 00 00 02 03 03 03 04 06 08 0B 0C 0C 0F

					//add uir config
					39 00 00 40 00 00 06 F0 55 AA 52 08 00
					15 00 00 40 00 00 02 6F 78
					39 00 00 40 00 00 18 B0 17 00 2A 00 C2 01 DA 03 7C 05 B1 08 80 0B EE 0F FF 05 55 05 56 05 55
					//APL_BLK_R_NUM,APL_BLK_G_NUM,APL_BLK_B_NUM
					15 00 00 40 00 00 02 6F 6F
					39 00 00 40 00 00 07 B0 02 D0 05 A0 02 D0
					//Data Scale Ratio
					39 00 00 40 00 00 06 F0 55 AA 52 08 08
					//DS_LV0_APL0
					39 00 00 40 00 00 17 C1 8E 33 EE 33 33 EE 33 33 EE 33 33 EE 33 33 BE 33 AC 9B AC 0D 0F FF
					//HBM_LV
					15 00 00 40 00 00 02 6F 1D
					39 00 00 40 00 00 03 C1 00 FF
					//APL_L/APL_H
					15 00 00 40 00 00 02 6F 20
					39 00 00 40 00 00 04 C1 0F 29 FF
					//DS_LV0_APL1
					15 00 00 40 00 00 02 6F 23
					39 00 00 40 00 00 15 C1 0E 33 EE 33 33 EE 33 33 EE 33 33 EE 33 33 BE 33 AC 9B AC 0D
					//DS_Lv1_Apl0
					15 00 00 40 00 00 02 6F 37
					39 00 00 40 00 00 15 C1 0F FF FF FF FF FF FF FF FF FF FF FF FF FF DF FF 27 AD 27 33
					//DS_Lv1_Apl1
					15 00 00 40 00 00 02 6F 4B
					39 00 00 40 00 00 15 C1 0E 33 EE 33 33 EE 33 33 EE 33 33 EE 33 33 BE 33 AC 9B AC 0D
					//DS_LV2_APL0
					15 00 00 40 00 00 02 6F 5F
					39 00 00 40 00 00 15 C1 0F FF FF FF FF FF FF FF FF FF FF FF FF FF FF FF FF FF FF FF
					//DS_LV2_APL1
					15 00 00 40 00 00 02 6F 73
					39 00 00 40 00 00 15 C1 0E 33 EE 33 33 EE 33 33 EE 33 33 EE 33 33 BE 33 AC 9B AC 0D
					//DS_DBV_TH
					39 00 00 40 00 00 11 BA 00 01 00 8A 00 8A 01 3C 01 3C 01 9D 01 9D 02 79
					15 00 00 40 00 00 02 6F 10
					39 00 00 40 00 00 11 BA 02 79 03 7D 03 7D 04 93 04 93 06 98 06 98 0A E2
					15 00 00 40 00 00 02 6F 20
					39 00 00 40 00 00 0D BA 0A E2 0D BB 0D BB 0F FE 0F FE 0F FF
					//GIR1.0
					15 00 00 40 00 00 02 6F 07
					15 00 00 00 00 00 02 51 00

					//Sleep out
					15 00 00 00 78 00 02 11 00
					//Display out
					15 00 00 00 00 00 02 29 00
					//scale up off
					39 00 00 40 00 00 05 2A 00 00 05 9F
					39 00 00 40 00 00 05 2B 00 00 0C 3F
					39 00 00 40 00 00 02 03 00
					39 00 00 40 00 00 02 8F 00
					//OSC Trim
					39 00 00 40 00 00 50 A9 02 01 C3 02 03 02 87 02 01 C3 08 08 87 02 01 C3 0B 0D 3F 39 4B 02 01 C3 0E 0F 3F 46 02 01 C3 10 10 DD 02 01 C3 11 13 3F 39 4B 02 01 C3 14 16 3F 46 DD 02 01 C3 23 25 3F 38 FC 02 01 C3 26 27 3F 2C 02 01 C3 28 28 A8 02 01 C3 29 2B 11 00 00
					//DSC setting lock
					39 00 00 40 00 00 07 A9 02 00 D8 0D 0D 42
					//FPS setting 60Hz
					39 00 00 00 01 00 8F A9 01 00 2F 00 00 03 02 09 BD 00 00 05 02 08 B7 08 0F 00 C8 00 C8 02 58 02 58 02 08 B7 10 1F 03 E8 03 E8 03 E8 03 E8 05 DC 05 DC 07 D0 07 D0 02 08 B7 20 27 09 C4 09 C4 08 FC 08 FC 02 08 B7 28 2D 08 00 08 00 08 00 01 00 A2 00 20 07 02 01 DD 02 03 00 00 00 00 00 00 00 00 02 04 B5 02 03 00 03 00 00 00 00 00 00 01 00 9D 00 00 AA 01 00 8D 02 02 01 01 00 A3 00 0F 81 00 00 00 00 02 09 BD 00 00 04 00 00 00 00 00 01 00 A3 10 11 00 00
				];

				qcom,lm-split = <720 720>;
				qcom,mdss-dsc-slice-height = <16>;
				qcom,mdss-dsc-slice-width = <720>;
			};
			timing@wqhd_sdc_144 {
				#include "dsi-panel-AE084-P-3-A0033-common.dtsi"
				#include "dsi-panel-AE084-P-3-A0033-common-effect.dtsi"
				cell-index = <3>;
				qcom,mdss-mdp-transfer-time-us = <6800>;
				qcom,mdss-dsi-panel-framerate = <144>;
				qcom,mdss-dsi-panel-clockrate = <1452000000>;
				qcom,mdss-dsi-panel-width = <1440>;
				qcom,mdss-dsi-panel-height = <3136>;

				qcom,mdss-dsi-h-front-porch = <16>;
				qcom,mdss-dsi-h-back-porch = <16>;
				qcom,mdss-dsi-h-pulse-width = <2>;
				qcom,mdss-dsi-v-back-porch = <28>;
				qcom,mdss-dsi-v-front-porch = <78>;
				qcom,mdss-dsi-v-pulse-width = <2>;
				qcom,mdss-dsi-h-sync-pulse = <0>;

				oplus,ofp-need-to-sync-data-in-aod-unlocking;
				oplus,ofp-aod-off-insert-black-frame = <1>;
				oplus,ofp-aod-off-black-frame-total-time = <42>;
				oplus,ofp-need-to-separate-backlight;
				oplus,ofp-backlight-on-period = <1>;

				qcom,mdss-dsi-timing-switch-command = [
					// OD setting
					39 00 00 40 00 00 47 A9 02 08 E0 00 00 40 02 08 E1 01 02 20 04 02 08 E2 01 02 20 04 02 08 E1 0F 0F 16 02 08 E1 10 10 08 02 08 E2 0F 0F 1C 02 08 E2 10 10 0A 02 08 E1 1D 1E 0D 04 02 08 E2 1D 1E 12 06 02 08 E1 2B 2B 0A 02 08 E2 2B 2B 12
					39 00 00 40 00 00 45 A9 02 08 E1 39 3A 08 04 02 08 E2 39 3A 0A 04 02 08 E1 47 47 06 02 08 E2 47 47 06 02 08 E1 55 55 06 02 08 E2 55 55 06 02 08 E1 63 63 02 02 08 E2 63 63 02 02 08 E1 71 71 02 02 08 E2 71 71 02 02 08 E0 00 00 41
					//DSC setting unlock
					39 00 00 40 00 00 06 F0 55 AA 52 08 00
					39 00 00 40 00 00 02 6F 0D
					39 00 00 40 00 00 02 D8 40
					//DSC SET
					39 00 00 40 00 00 03 90 03 43
					39 00 00 40 00 00 13 91 AB A8 00 10 C2 00 02 68 01 BB 00 0A 06 67 04 C5 10 F0
					39 00 00 40 00 00 13 93 AB A8 00 10 C2 00 02 0E 01 84 00 07 06 67 06 5C 10 F0
					//Resolution binding
					39 00 00 40 00 00 05 2A 00 00 05 9F
					39 00 00 40 00 00 05 2B 00 00 0C 3F
					//DSC setting unlock
					39 00 00 40 00 00 06 F0 55 AA 52 08 00
					39 00 00 40 00 00 02 6F 0D
					39 00 00 40 00 00 02 D8 40
					//scale up off
					39 00 00 40 00 00 02 03 00
					39 00 00 40 00 00 02 8F 00
					//OSC Trim
					39 00 00 40 00 00 50 A9 02 01 C3 02 03 02 87 02 01 C3 08 08 87 02 01 C3 0B 0D 3F 39 4B 02 01 C3 0E 0F 3F 46 02 01 C3 10 10 DD 02 01 C3 11 13 3F 39 4B 02 01 C3 14 16 3F 46 DD 02 01 C3 23 25 3F 31 49 02 01 C3 26 27 3F 57 02 01 C3 28 28 DC 02 01 C3 29 2B 11 00 01
					//DSC setting lock
					39 00 00 40 00 00 06 F0 55 AA 52 08 00
					39 00 00 40 00 00 02 6F 0D
					39 00 00 40 00 00 02 D8 42
					//FPS setting 144Hz
					39 00 00 00 01 00 8F A9 01 00 2F 00 00 00 02 09 BD 00 00 05 02 08 B7 08 0F 02 58 02 58 04 B0 04 B0 02 08 B7 10 1F 07 6C 07 6C 07 08 07 08 0A 28 0A 28 0B B8 0B B8 02 08 B7 20 27 0D AC 0D AC 0C E4 0C E4 02 08 B7 28 2D 0B B8 0B B8 0B B8 01 00 A2 00 20 07 02 01 DD 02 03 05 BE 00 00 00 00 00 00 02 04 B5 02 03 00 0C 00 00 00 00 00 00 01 00 9D 00 00 AA 01 00 8D 02 02 01 01 00 A3 00 0F 81 00 00 00 00 02 09 BD 00 00 04 00 00 00 00 00 01 00 A3 10 11 00 00
					39 00 00 00 00 00 06 F0 55 AA 52 08 FF
				];
				qcom,mdss-dsi-on-command = [
					//GPIO setting
					39 00 00 40 00 00 06 F0 55 AA 52 08 00
					39 00 00 40 00 00 05 BE 49 47 47 4A
					//APL BLK Setting
					39 00 00 40 00 00 06 F0 55 AA 52 08 00
					39 00 00 40 00 00 02 6F 78
					39 00 00 40 00 00 18 B0 11 00 2A 00 C2 01 DA 03 7C 05 B1 08 80 0B EE 0F FF 05 55 05 56 05 55
					//APL_BLK_R_NUM,APL_BLK_G_NUM,APL_BLK_B_NUM
					39 00 00 40 00 00 02 6F 6F
					39 00 00 40 00 00 07 B0 02 D0 05 A0 02 D0
					//Data Scale Ratio
					39 00 00 40 00 00 06 F0 55 AA 52 08 08
					39 00 00 40 00 00 17 C1 8E 33 EE 33 33 EE 33 33 EE 33 33 EE 33 33 BE 33 AC 9B AC 0D 0F FF
					39 00 00 40 00 00 02 6F 23
					39 00 00 40 00 00 15 C1 0E 33 EE 33 33 EE 33 33 EE 33 33 EE 33 33 BE 33 AC 9B AC 0D
					39 00 00 40 00 00 02 6F 37
					39 00 00 40 00 00 15 C1 0F FF FF FF FF FF FF FF FF FF FF FF FF FF DF FF 27 AD 27 33
					39 00 00 40 00 00 02 6F 4B
					39 00 00 40 00 00 15 C1 0E 33 EE 33 33 EE 33 33 EE 33 33 EE 33 33 BE 33 AC 9B AC 0D
					39 00 00 40 00 00 02 6F 5F
					39 00 00 40 00 00 15 C1 0F FF FF FF FF FF FF FF FF FF FF FF FF FF FF FF FF FF FF FF
					39 00 00 40 00 00 02 6F 73
					39 00 00 40 00 00 15 C1 0E 33 EE 33 33 EE 33 33 EE 33 33 EE 33 33 BE 33 AC 9B AC 0D
					//DS_DBV_TH
					39 00 00 40 00 00 11 BA 00 01 00 8A 00 8A 01 3C 01 3C 01 9D 01 9D 02 79
					39 00 00 40 00 00 02 6F 10
					39 00 00 40 00 00 11 BA 02 79 03 7D 03 7D 04 93 04 93 06 98 06 98 0A E2
					39 00 00 40 00 00 02 6F 20
					39 00 00 40 00 00 0D BA 0A E2 0D BB 0D BB 0F FE 0F FE 0F FF
					//APL_L/APL_H
					39 00 00 40 00 00 02 6F 20
					39 00 00 40 00 00 04 C1 0F 29 FF
					//HBM_LV0/1/2
					39 00 00 40 00 00 02 6F 1D
					39 00 00 40 00 00 04 C1 00 80 FF
					39 00 00 40 00 00 05 FF AA 55 A5 80
					//OSC Charge up 4uA
					39 00 00 40 00 00 02 6F 07
					39 00 00 40 00 00 02 F8 4D
					39 00 00 40 00 00 02 6F 23
					39 00 00 40 00 00 02 F8 4D
					//mtp_vgh_setting
					39 00 00 40 00 00 02 6F 04
					39 00 00 40 00 00 02 F2 1D
					//power on/off sequence
					39 00 00 40 00 00 02 6F 0A
					39 00 00 40 00 00 06 F6 70 70 70 70 70
					// stop_hclk_fskip & stop_hclk_vfp = 1
					39 00 00 40 00 00 05 FF AA 55 A5 81
					39 00 00 40 00 00 02 6F 0E
					39 00 00 40 00 00 02 F5 2B
					//bois clk,idle vfp clk off
					39 00 00 40 00 00 02 6F 0F
					39 00 00 40 00 00 02 F5 22
					// porch source setting
					39 00 00 40 00 00 02 6F 05
					39 00 00 40 00 00 03 FE 3C 3C
					//mipi timing optimize
					39 00 00 40 00 00 05 FF AA 55 A5 82
					39 00 00 40 00 00 02 6F 12
					39 00 00 40 00 00 03 F2 23 25
					//source status @ mtp status = hi-z
					39 00 00 40 00 00 06 F0 55 AA 52 08 00
					39 00 00 40 00 00 02 6F 04
					39 00 00 40 00 00 02 C2 32
					//Blue spot optimization
					39 00 00 40 00 00 06 F0 55 AA 52 08 00
					39 00 00 40 00 00 02 6F 31
					39 00 00 40 00 00 04 C0 00 22 00
					39 00 00 40 00 00 06 F0 55 AA 52 08 00
					39 00 00 40 00 00 02 6F 39
					39 00 00 40 00 00 04 C0 11 33 00
					//scaling up setting
					39 00 00 40 00 00 02 6F 0D
					39 00 00 40 00 00 02 D8 40
					39 00 00 40 00 00 02 C0 44
					//goa status @ mtp status = toggle
					39 00 00 40 00 00 06 F0 55 AA 52 08 01
					39 00 00 40 00 00 02 6F 08
					39 00 00 40 00 00 02 CA 00
					//keep command mode
					39 00 00 40 00 00 05 FF AA 55 A5 00
					39 00 00 40 00 00 06 F0 55 AA 52 00 00
					39 00 00 40 00 00 02 6F 02
					39 00 00 40 00 00 02 17 12
					39 00 00 40 00 00 02 35 08
					//BC Dimming OFF
					39 00 00 40 00 00 02 53 20
					//H_res = 1440 , V_res = 3136
					39 00 00 40 00 00 05 2a 00 00 05 9f
					39 00 00 40 00 00 05 2b 00 00 0C 3f
					//normal gma
					39 00 00 40 00 00 02 26 00
					//normal dbv
					39 00 00 40 00 00 03 51 00 00
					//idle dbv
					39 00 00 40 00 00 02 6F 04
					39 00 00 40 00 00 03 51 0D BB
					//LFCC LUT Table Sel
					39 00 00 40 00 00 02 68 00
					//md1,dpc temperature
					39 00 00 40 00 00 03 81 01 19
					//DSC setting unlock
					39 00 00 40 00 00 07 A9 02 00 D8 0D 0D 40
					//DSC SET
					39 00 00 40 00 00 03 90 03 43
					39 00 00 40 00 00 13 91 AB A8 00 10 C2 00 02 68 01 BB 00 0A 06 67 04 C5 10 F0
					39 00 00 00 00 00 13 93 AB A8 00 10 C2 00 02 0E 01 84 00 07 06 67 06 5C 10 F0
					//vdc & peak luminance
					39 00 00 40 00 00 03 5F 00 C0
					39 00 00 40 00 00 02 6F 07
					39 00 00 40 00 00 02 51 00
					//1nit rolling horizontal stripes
					39 00 00 40 00 00 06 F0 55 AA 52 08 00
					39 00 00 40 00 00 02 6F 62
					39 00 00 40 00 00 02 D5 0F
					39 00 00 40 00 00 02 6F 68
					39 00 00 40 00 00 02 D5 10
					//RND OFF
					39 00 00 40 00 00 06 F0 55 AA 52 08 07
					39 00 00 40 00 00 02 C0 06

					//OSC Trim
					39 00 00 40 00 00 06 F0 55 AA 52 08 01
					39 00 00 40 00 00 36 C3 99 29 02 87 19 00 29 00 87 19 00 3F 39 4B 3F 46 DD 3F 39 4B 3F 46 DD 3F 51 FE 3F 25 A9 3F 51 FE 3F 25 A9 3F 38 FC 3F 2C A8 11 00 00 00 00 00 77 00 AA 02 AA 02
					15 00 00 40 00 00 02 6F 04
					15 00 00 40 00 00 02 C3 19
					15 00 00 40 00 00 02 6F 09
					15 00 00 40 00 00 02 C3 19

					// OD setting
					39 00 00 40 00 00 06 F0 55 AA 52 08 08
					39 00 00 40 00 00 05 E0 41 01 01 01
					39 00 00 40 00 00 02 6F 06
					39 00 00 40 00 00 0E E0 80 00 21 32 43 54 65 76 87 98 99 99 99
					39 00 00 40 00 00 0F E1 03 20 04 0D 0E 0F 0F 10 12 14 14 17 1C 20
					39 00 00 40 00 00 0F E2 03 20 04 0A 0C 0E 10 12 17 1A 1E 1F 20 21
					39 00 00 40 00 00 0F E3 00 00 00 00 00 00 00 00 00 00 00 00 00 00
					39 00 00 40 00 00 02 6F 0E
					39 00 00 40 00 00 0F E1 03 16 08 0A 0B 0B 0C 0D 0E 0E 12 14 17 20
					39 00 00 40 00 00 02 6F 0E
					39 00 00 40 00 00 0F E2 03 1C 0A 0F 10 10 11 12 13 13 14 15 17 19
					39 00 00 40 00 00 02 6F 0E
					39 00 00 40 00 00 0F E3 00 00 00 00 00 00 00 00 00 00 00 00 00 00
					39 00 00 40 00 00 02 6F 1C
					39 00 00 40 00 00 0F E1 02 0D 04 0A 0A 0A 0A 0A 0A 0A 0B 0B 0D 0F
					39 00 00 40 00 00 02 6F 1C
					39 00 00 40 00 00 0F E2 02 12 06 06 06 07 08 08 08 08 08 0A 0C 0D
					39 00 00 40 00 00 02 6F 1C
					39 00 00 40 00 00 0F E3 00 00 00 04 04 04 04 04 07 07 08 08 0C 0F
					39 00 00 40 00 00 02 6F 2A
					39 00 00 40 00 00 0F E1 01 0A 04 05 05 06 07 08 08 0A 0B 0B 0E 13
					39 00 00 40 00 00 02 6F 2A
					39 00 00 40 00 00 0F E2 02 12 04 08 08 08 08 08 08 08 0A 0B 0D 11
					39 00 00 40 00 00 02 6F 2A
					39 00 00 40 00 00 0F E3 00 00 00 03 03 03 03 03  03 07 09 0B 0D 12
					39 00 00 40 00 00 02 6F 38
					39 00 00 40 00 00 0F E1 01 08 04 05 05 05 05 05 06 09 0A 0B 0D 11
					39 00 00 40 00 00 02 6F 38
					39 00 00 40 00 00 0F E2 01 0A 04 05 05 05 06 06 06 07 09 0B 0D 10
					39 00 00 40 00 00 02 6F 38
					39 00 00 40 00 00 0F E3 00 00 00 04 04 04 04 04 05 07 08 0A 0D 0F
					39 00 00 40 00 00 02 6F 46
					39 00 00 40 00 00 0F E1 01 06 03 05 05 05 05 05 06 08 09 0B 0C 0F
					39 00 00 40 00 00 02 6F 46
					39 00 00 40 00 00 0F E2 01 06 03 04 04 04 04 04 06 08 09 0A 0C 0F
					39 00 00 40 00 00 02 6F 46
					39 00 00 40 00 00 0F E3 00 00 00 03 03 03 03 03 06 08 09 0A 0C 10
					39 00 00 40 00 00 02 6F 54
					39 00 00 40 00 00 0F E1 01 06 03 04 04 04 04 04 06 08 09 0A 0B 0F
					39 00 00 40 00 00 02 6F 54
					39 00 00 40 00 00 0F E2 01 06 03 04 04 04 04 04 06 07 09 0A 0B 0E
					39 00 00 40 00 00 02 6F 54
					39 00 00 40 00 00 0F E3 00 00 00 02 02 03 03 04 05 07 09 0C 0E 12
					39 00 00 40 00 00 02 6F 62
					39 00 00 40 00 00 0F E1 01 02 02 03 03 04 04 04 06 07 08 0A 0C 0F
					39 00 00 40 00 00 02 6F 62
					39 00 00 40 00 00 0F E2 01 02 02 02 03 03 03 04 05 07 08 09 0A 0E
					39 00 00 40 00 00 02 6F 62
					39 00 00 40 00 00 0F E3 00 00 00 02 02 03 03 04 06 08 0A 0D 0E 12
					39 00 00 40 00 00 02 6F 70
					39 00 00 40 00 00 0F E1 01 02 02 02 03 03 03 04 05 07 09 0C 0D 11
					39 00 00 40 00 00 02 6F 70
					39 00 00 40 00 00 0F E2 01 02 02 02 03 03 03 04 05 07 09 0B 0C 0F
					39 00 00 40 00 00 02 6F 70
					39 00 00 40 00 00 0F E3 00 00 00 02 03 03 03 04 06 08 0B 0C 0C 0F

					//add uir config
					39 00 00 40 00 00 06 F0 55 AA 52 08 00
					15 00 00 40 00 00 02 6F 78
					39 00 00 40 00 00 18 B0 17 00 2A 00 C2 01 DA 03 7C 05 B1 08 80 0B EE 0F FF 05 55 05 56 05 55
					//APL_BLK_R_NUM,APL_BLK_G_NUM,APL_BLK_B_NUM
					15 00 00 40 00 00 02 6F 6F
					39 00 00 40 00 00 07 B0 02 D0 05 A0 02 D0
					//Data Scale Ratio
					39 00 00 40 00 00 06 F0 55 AA 52 08 08
					//DS_LV0_APL0
					39 00 00 40 00 00 17 C1 8E 33 EE 33 33 EE 33 33 EE 33 33 EE 33 33 BE 33 AC 9B AC 0D 0F FF
					//HBM_LV
					15 00 00 40 00 00 02 6F 1D
					39 00 00 40 00 00 03 C1 00 FF
					//APL_L/APL_H
					15 00 00 40 00 00 02 6F 20
					39 00 00 40 00 00 04 C1 0F 29 FF
					//DS_LV0_APL1
					15 00 00 40 00 00 02 6F 23
					39 00 00 40 00 00 15 C1 0E 33 EE 33 33 EE 33 33 EE 33 33 EE 33 33 BE 33 AC 9B AC 0D
					//DS_Lv1_Apl0
					15 00 00 40 00 00 02 6F 37
					39 00 00 40 00 00 15 C1 0F FF FF FF FF FF FF FF FF FF FF FF FF FF DF FF 27 AD 27 33
					//DS_Lv1_Apl1
					15 00 00 40 00 00 02 6F 4B
					39 00 00 40 00 00 15 C1 0E 33 EE 33 33 EE 33 33 EE 33 33 EE 33 33 BE 33 AC 9B AC 0D
					//DS_LV2_APL0
					15 00 00 40 00 00 02 6F 5F
					39 00 00 40 00 00 15 C1 0F FF FF FF FF FF FF FF FF FF FF FF FF FF FF FF FF FF FF FF
					//DS_LV2_APL1
					15 00 00 40 00 00 02 6F 73
					39 00 00 40 00 00 15 C1 0E 33 EE 33 33 EE 33 33 EE 33 33 EE 33 33 BE 33 AC 9B AC 0D
					//DS_DBV_TH
					39 00 00 40 00 00 11 BA 00 01 00 8A 00 8A 01 3C 01 3C 01 9D 01 9D 02 79
					15 00 00 40 00 00 02 6F 10
					39 00 00 40 00 00 11 BA 02 79 03 7D 03 7D 04 93 04 93 06 98 06 98 0A E2
					15 00 00 40 00 00 02 6F 20
					39 00 00 40 00 00 0D BA 0A E2 0D BB 0D BB 0F FE 0F FE 0F FF
					//GIR1.0
					15 00 00 40 00 00 02 6F 07
					15 00 00 00 00 00 02 51 00

					//Sleep out
					15 00 00 00 78 00 02 11 00
					//Display out
					15 00 00 00 00 00 02 29 00
					//scale up off
					39 00 00 40 00 00 05 2A 00 00 05 9F
					39 00 00 40 00 00 05 2B 00 00 0C 3F
					39 00 00 40 00 00 02 03 00
					39 00 00 40 00 00 02 8F 00
					//OSC Trim
					39 00 00 40 00 00 50 A9 02 01 C3 02 03 02 87 02 01 C3 08 08 87 02 01 C3 0B 0D 3F 39 4B 02 01 C3 0E 0F 3F 46 02 01 C3 10 10 DD 02 01 C3 11 13 3F 39 4B 02 01 C3 14 16 3F 46 DD 02 01 C3 23 25 3F 31 49 02 01 C3 26 27 3F 57 02 01 C3 28 28 DC 02 01 C3 29 2B 11 00 01
					//DSC setting lock
					39 00 00 40 00 00 07 A9 02 00 D8 0D 0D 42
					//FPS setting 144Hz
					39 00 00 00 01 00 8F A9 01 00 2F 00 00 00 02 09 BD 00 00 05 02 08 B7 08 0F 02 58 02 58 04 B0 04 B0 02 08 B7 10 1F 07 6C 07 6C 07 08 07 08 0A 28 0A 28 0B B8 0B B8 02 08 B7 20 27 0D AC 0D AC 0C E4 0C E4 02 08 B7 28 2D 0B B8 0B B8 0B B8 01 00 A2 00 20 07 02 01 DD 02 03 05 BE 00 00 00 00 00 00 02 04 B5 02 03 00 0C 00 00 00 00 00 00 01 00 9D 00 00 AA 01 00 8D 02 02 01 01 00 A3 00 0F 81 00 00 00 00 02 09 BD 00 00 04 00 00 00 00 00 01 00 A3 10 11 00 00
				];

				qcom,lm-split = <720 720>;
				qcom,mdss-dsc-slice-height = <16>;
				qcom,mdss-dsc-slice-width = <720>;
			};

			//1080P
			timing@fhd_sdc_120 {
				#include "dsi-panel-AE084-P-3-A0033-common.dtsi"
				#include "dsi-panel-AE084-P-3-A0033-common-effect.dtsi"
				cell-index = <4>;
				qcom,mdss-mdp-transfer-time-us = <6800>;
				qcom,mdss-dsi-panel-framerate = <120>;
				qcom,mdss-dsi-panel-clockrate = <1113600000>;
				qcom,mdss-dsi-panel-width = <1080>;
				qcom,mdss-dsi-panel-height = <2352>;

				qcom,mdss-dsi-h-front-porch = <16>;
				qcom,mdss-dsi-h-back-porch = <16>;
				qcom,mdss-dsi-h-pulse-width = <2>;
				qcom,mdss-dsi-v-back-porch = <28>;
				qcom,mdss-dsi-v-front-porch = <78>;
				qcom,mdss-dsi-v-pulse-width = <2>;
				qcom,mdss-dsi-h-sync-pulse = <0>;

				oplus,ofp-need-to-sync-data-in-aod-unlocking;
				oplus,ofp-aod-off-insert-black-frame = <1>;
				oplus,ofp-aod-off-black-frame-total-time = <42>;
				oplus,ofp-need-to-separate-backlight;
				oplus,ofp-backlight-on-period = <1>;

				qcom,mdss-dsi-timing-switch-command = [
					// OD setting
					39 00 00 40 00 00 47 A9 02 08 E0 00 00 40 02 08 E1 01 02 20 04 02 08 E2 01 02 20 04 02 08 E1 0F 0F 16 02 08 E1 10 10 08 02 08 E2 0F 0F 1C 02 08 E2 10 10 0A 02 08 E1 1D 1E 0D 04 02 08 E2 1D 1E 12 06 02 08 E1 2B 2B 0A 02 08 E2 2B 2B 12
					39 00 00 40 00 00 45 A9 02 08 E1 39 3A 08 04 02 08 E2 39 3A 0A 04 02 08 E1 47 47 06 02 08 E2 47 47 06 02 08 E1 55 55 06 02 08 E2 55 55 06 02 08 E1 63 63 02 02 08 E2 63 63 02 02 08 E1 71 71 02 02 08 E2 71 71 02 02 08 E0 00 00 41
					//DSC setting unlock
					39 00 00 40 00 00 06 F0 55 AA 52 08 00
					39 00 00 40 00 00 02 6F 0D
					39 00 00 40 00 00 02 D8 40
					//DSC SET
					39 00 00 40 00 00 03 90 03 43
					39 00 00 40 00 00 13 91 AB A8 00 10 C2 00 02 68 01 BB 00 0A 06 67 04 C5 10 F0
					39 00 00 40 00 00 13 93 AB A8 00 10 C2 00 02 0E 01 84 00 07 06 67 06 5C 10 F0
					//Resolution binding
					39 00 00 40 00 00 05 2A 00 00 04 37
					39 00 00 40 00 00 05 2B 00 00 09 2F
					//DSC setting unlock
					39 00 00 40 00 00 06 F0 55 AA 52 08 00
					39 00 00 40 00 00 02 6F 0D
					39 00 00 40 00 00 02 D8 40
					//scale up on
					39 00 00 40 00 00 02 03 10
					39 00 00 40 00 00 02 8F 01
					//OSC Trim
					39 00 00 40 00 00 50 A9 02 01 C3 02 03 02 67 02 01 C3 08 08 67 02 01 C3 0B 0D 3F 51 FE 02 01 C3 0E 0F 3F 25 02 01 C3 10 10 A9 02 01 C3 11 13 3F 51 FE 02 01 C3 14 16 3F 25 A9 02 01 C3 23 25 3F 38 FC 02 01 C3 26 27 3F 2C 02 01 C3 28 28 A8 02 01 C3 29 2B 00 00 00
					//DSC setting lock
					39 00 00 40 00 00 06 F0 55 AA 52 08 00
					39 00 00 40 00 00 02 6F 0D
					39 00 00 40 00 00 02 D8 42
					//Fcon setting 120Hz
					39 00 00 00 01 00 8F A9 01 00 2F 00 00 01 02 09 BD 00 00 05 02 08 B7 08 0F 00 C8 00 C8 02 58 02 58 02 08 B7 10 1F 03 E8 03 E8 03 E8 03 E8 05 DC 05 DC 07 D0 07 D0 02 08 B7 20 27 09 C4 09 C4 08 FC 08 FC 02 08 B7 28 2D 08 00 08 00 08 00 01 00 A2 00 20 07 02 01 DD 02 03 00 00 00 00 00 00 00 00 02 04 B5 02 03 00 03 00 00 00 00 00 00 01 00 9D 00 00 AA 01 00 8D 02 02 01 01 00 A3 00 0F 81 00 00 00 00 02 09 BD 00 00 04 00 00 00 00 00 01 00 A3 10 11 00 00
					39 00 00 00 00 00 06 F0 55 AA 52 08 FF
				];
				qcom,mdss-dsi-on-command = [
					//GPIO setting
					39 00 00 40 00 00 06 F0 55 AA 52 08 00
					39 00 00 40 00 00 05 BE 49 47 47 4A
					//APL BLK Setting
					39 00 00 40 00 00 06 F0 55 AA 52 08 00
					39 00 00 40 00 00 02 6F 78
					39 00 00 40 00 00 18 B0 11 00 2A 00 C2 01 DA 03 7C 05 B1 08 80 0B EE 0F FF 05 55 05 56 05 55
					//APL_BLK_R_NUM,APL_BLK_G_NUM,APL_BLK_B_NUM
					39 00 00 40 00 00 02 6F 6F
					39 00 00 40 00 00 07 B0 02 D0 05 A0 02 D0
					//Data Scale Ratio
					39 00 00 40 00 00 06 F0 55 AA 52 08 08
					39 00 00 40 00 00 17 C1 8E 33 EE 33 33 EE 33 33 EE 33 33 EE 33 33 BE 33 AC 9B AC 0D 0F FF
					39 00 00 40 00 00 02 6F 23
					39 00 00 40 00 00 15 C1 0E 33 EE 33 33 EE 33 33 EE 33 33 EE 33 33 BE 33 AC 9B AC 0D
					39 00 00 40 00 00 02 6F 37
					39 00 00 40 00 00 15 C1 0F FF FF FF FF FF FF FF FF FF FF FF FF FF DF FF 27 AD 27 33
					39 00 00 40 00 00 02 6F 4B
					39 00 00 40 00 00 15 C1 0E 33 EE 33 33 EE 33 33 EE 33 33 EE 33 33 BE 33 AC 9B AC 0D
					39 00 00 40 00 00 02 6F 5F
					39 00 00 40 00 00 15 C1 0F FF FF FF FF FF FF FF FF FF FF FF FF FF FF FF FF FF FF FF
					39 00 00 40 00 00 02 6F 73
					39 00 00 40 00 00 15 C1 0E 33 EE 33 33 EE 33 33 EE 33 33 EE 33 33 BE 33 AC 9B AC 0D
					//DS_DBV_TH
					39 00 00 40 00 00 11 BA 00 01 00 8A 00 8A 01 3C 01 3C 01 9D 01 9D 02 79
					39 00 00 40 00 00 02 6F 10
					39 00 00 40 00 00 11 BA 02 79 03 7D 03 7D 04 93 04 93 06 98 06 98 0A E2
					39 00 00 40 00 00 02 6F 20
					39 00 00 40 00 00 0D BA 0A E2 0D BB 0D BB 0F FE 0F FE 0F FF
					//APL_L/APL_H
					39 00 00 40 00 00 02 6F 20
					39 00 00 40 00 00 04 C1 0F 29 FF
					//HBM_LV0/1/2
					39 00 00 40 00 00 02 6F 1D
					39 00 00 40 00 00 04 C1 00 80 FF
					39 00 00 40 00 00 05 FF AA 55 A5 80
					//OSC Charge up 4uA
					39 00 00 40 00 00 02 6F 07
					39 00 00 40 00 00 02 F8 4D
					39 00 00 40 00 00 02 6F 23
					39 00 00 40 00 00 02 F8 4D
					//mtp_vgh_setting
					39 00 00 40 00 00 02 6F 04
					39 00 00 40 00 00 02 F2 1D
					//power on/off sequence
					39 00 00 40 00 00 02 6F 0A
					39 00 00 40 00 00 06 F6 70 70 70 70 70
					// stop_hclk_fskip & stop_hclk_vfp = 1
					39 00 00 40 00 00 05 FF AA 55 A5 81
					39 00 00 40 00 00 02 6F 0E
					39 00 00 40 00 00 02 F5 2B
					//bois clk,idle vfp clk off
					39 00 00 40 00 00 02 6F 0F
					39 00 00 40 00 00 02 F5 22
					// porch source setting
					39 00 00 40 00 00 02 6F 05
					39 00 00 40 00 00 03 FE 3C 3C
					//mipi timing optimize
					39 00 00 40 00 00 05 FF AA 55 A5 82
					39 00 00 40 00 00 02 6F 12
					39 00 00 40 00 00 03 F2 23 25
					//source status @ mtp status = hi-z
					39 00 00 40 00 00 06 F0 55 AA 52 08 00
					39 00 00 40 00 00 02 6F 04
					39 00 00 40 00 00 02 C2 32
					//Blue spot optimization
					39 00 00 40 00 00 06 F0 55 AA 52 08 00
					39 00 00 40 00 00 02 6F 31
					39 00 00 40 00 00 04 C0 00 22 00
					39 00 00 40 00 00 06 F0 55 AA 52 08 00
					39 00 00 40 00 00 02 6F 39
					39 00 00 40 00 00 04 C0 11 33 00
					//scaling up setting
					39 00 00 40 00 00 02 6F 0D
					39 00 00 40 00 00 02 D8 40
					39 00 00 40 00 00 02 C0 44
					//goa status @ mtp status = toggle
					39 00 00 40 00 00 06 F0 55 AA 52 08 01
					39 00 00 40 00 00 02 6F 08
					39 00 00 40 00 00 02 CA 00
					//keep command mode
					39 00 00 40 00 00 05 FF AA 55 A5 00
					39 00 00 40 00 00 06 F0 55 AA 52 00 00
					39 00 00 40 00 00 02 6F 02
					39 00 00 40 00 00 02 17 12
					39 00 00 40 00 00 02 35 08
					//BC Dimming OFF
					39 00 00 40 00 00 02 53 20
					//H_res = 1440 , V_res = 3136
					39 00 00 40 00 00 05 2a 00 00 05 9f
					39 00 00 40 00 00 05 2b 00 00 0C 3f
					//normal gma
					39 00 00 40 00 00 02 26 00
					//normal dbv
					39 00 00 40 00 00 03 51 00 00
					//idle dbv
					39 00 00 40 00 00 02 6F 04
					39 00 00 40 00 00 03 51 0D BB
					//LFCC LUT Table Sel
					39 00 00 40 00 00 02 68 00
					//md1,dpc temperature
					39 00 00 40 00 00 03 81 01 19
					//DSC setting unlock
					39 00 00 40 00 00 07 A9 02 00 D8 0D 0D 40
					//DSC SET
					39 00 00 40 00 00 03 90 03 43
					39 00 00 40 00 00 13 91 AB A8 00 10 C2 00 02 68 01 BB 00 0A 06 67 04 C5 10 F0
					39 00 00 00 00 00 13 93 AB A8 00 10 C2 00 02 0E 01 84 00 07 06 67 06 5C 10 F0
					//vdc & peak luminance
					39 00 00 40 00 00 03 5F 00 C0
					39 00 00 40 00 00 02 6F 07
					39 00 00 40 00 00 02 51 00
					//1nit rolling horizontal stripes
					39 00 00 40 00 00 06 F0 55 AA 52 08 00
					39 00 00 40 00 00 02 6F 62
					39 00 00 40 00 00 02 D5 0F
					39 00 00 40 00 00 02 6F 68
					39 00 00 40 00 00 02 D5 10
					//RND OFF
					39 00 00 40 00 00 06 F0 55 AA 52 08 07
					39 00 00 40 00 00 02 C0 06

					//OSC Trim
					39 00 00 40 00 00 06 F0 55 AA 52 08 01
					39 00 00 40 00 00 36 C3 99 29 02 87 19 00 29 00 87 19 00 3F 39 4B 3F 46 DD 3F 39 4B 3F 46 DD 3F 51 FE 3F 25 A9 3F 51 FE 3F 25 A9 3F 38 FC 3F 2C A8 11 00 00 00 00 00 77 00 AA 02 AA 02
					15 00 00 40 00 00 02 6F 04
					15 00 00 40 00 00 02 C3 19
					15 00 00 40 00 00 02 6F 09
					15 00 00 40 00 00 02 C3 19

					// OD setting
					39 00 00 40 00 00 06 F0 55 AA 52 08 08
					39 00 00 40 00 00 05 E0 41 01 01 01
					39 00 00 40 00 00 02 6F 06
					39 00 00 40 00 00 0E E0 80 00 21 32 43 54 65 76 87 98 99 99 99
					39 00 00 40 00 00 0F E1 03 20 04 0D 0E 0F 0F 10 12 14 14 17 1C 20
					39 00 00 40 00 00 0F E2 03 20 04 0A 0C 0E 10 12 17 1A 1E 1F 20 21
					39 00 00 40 00 00 0F E3 00 00 00 00 00 00 00 00 00 00 00 00 00 00
					39 00 00 40 00 00 02 6F 0E
					39 00 00 40 00 00 0F E1 03 16 08 0A 0B 0B 0C 0D 0E 0E 12 14 17 20
					39 00 00 40 00 00 02 6F 0E
					39 00 00 40 00 00 0F E2 03 1C 0A 0F 10 10 11 12 13 13 14 15 17 19
					39 00 00 40 00 00 02 6F 0E
					39 00 00 40 00 00 0F E3 00 00 00 00 00 00 00 00 00 00 00 00 00 00
					39 00 00 40 00 00 02 6F 1C
					39 00 00 40 00 00 0F E1 02 0D 04 0A 0A 0A 0A 0A 0A 0A 0B 0B 0D 0F
					39 00 00 40 00 00 02 6F 1C
					39 00 00 40 00 00 0F E2 02 12 06 06 06 07 08 08 08 08 08 0A 0C 0D
					39 00 00 40 00 00 02 6F 1C
					39 00 00 40 00 00 0F E3 00 00 00 04 04 04 04 04 07 07 08 08 0C 0F
					39 00 00 40 00 00 02 6F 2A
					39 00 00 40 00 00 0F E1 01 0A 04 05 05 06 07 08 08 0A 0B 0B 0E 13
					39 00 00 40 00 00 02 6F 2A
					39 00 00 40 00 00 0F E2 02 12 04 08 08 08 08 08 08 08 0A 0B 0D 11
					39 00 00 40 00 00 02 6F 2A
					39 00 00 40 00 00 0F E3 00 00 00 03 03 03 03 03  03 07 09 0B 0D 12
					39 00 00 40 00 00 02 6F 38
					39 00 00 40 00 00 0F E1 01 08 04 05 05 05 05 05 06 09 0A 0B 0D 11
					39 00 00 40 00 00 02 6F 38
					39 00 00 40 00 00 0F E2 01 0A 04 05 05 05 06 06 06 07 09 0B 0D 10
					39 00 00 40 00 00 02 6F 38
					39 00 00 40 00 00 0F E3 00 00 00 04 04 04 04 04 05 07 08 0A 0D 0F
					39 00 00 40 00 00 02 6F 46
					39 00 00 40 00 00 0F E1 01 06 03 05 05 05 05 05 06 08 09 0B 0C 0F
					39 00 00 40 00 00 02 6F 46
					39 00 00 40 00 00 0F E2 01 06 03 04 04 04 04 04 06 08 09 0A 0C 0F
					39 00 00 40 00 00 02 6F 46
					39 00 00 40 00 00 0F E3 00 00 00 03 03 03 03 03 06 08 09 0A 0C 10
					39 00 00 40 00 00 02 6F 54
					39 00 00 40 00 00 0F E1 01 06 03 04 04 04 04 04 06 08 09 0A 0B 0F
					39 00 00 40 00 00 02 6F 54
					39 00 00 40 00 00 0F E2 01 06 03 04 04 04 04 04 06 07 09 0A 0B 0E
					39 00 00 40 00 00 02 6F 54
					39 00 00 40 00 00 0F E3 00 00 00 02 02 03 03 04 05 07 09 0C 0E 12
					39 00 00 40 00 00 02 6F 62
					39 00 00 40 00 00 0F E1 01 02 02 03 03 04 04 04 06 07 08 0A 0C 0F
					39 00 00 40 00 00 02 6F 62
					39 00 00 40 00 00 0F E2 01 02 02 02 03 03 03 04 05 07 08 09 0A 0E
					39 00 00 40 00 00 02 6F 62
					39 00 00 40 00 00 0F E3 00 00 00 02 02 03 03 04 06 08 0A 0D 0E 12
					39 00 00 40 00 00 02 6F 70
					39 00 00 40 00 00 0F E1 01 02 02 02 03 03 03 04 05 07 09 0C 0D 11
					39 00 00 40 00 00 02 6F 70
					39 00 00 40 00 00 0F E2 01 02 02 02 03 03 03 04 05 07 09 0B 0C 0F
					39 00 00 40 00 00 02 6F 70
					39 00 00 40 00 00 0F E3 00 00 00 02 03 03 03 04 06 08 0B 0C 0C 0F

					//add uir config
					39 00 00 40 00 00 06 F0 55 AA 52 08 00
					15 00 00 40 00 00 02 6F 78
					39 00 00 40 00 00 18 B0 17 00 2A 00 C2 01 DA 03 7C 05 B1 08 80 0B EE 0F FF 05 55 05 56 05 55
					//APL_BLK_R_NUM,APL_BLK_G_NUM,APL_BLK_B_NUM
					15 00 00 40 00 00 02 6F 6F
					39 00 00 40 00 00 07 B0 02 D0 05 A0 02 D0
					//Data Scale Ratio
					39 00 00 40 00 00 06 F0 55 AA 52 08 08
					//DS_LV0_APL0
					39 00 00 40 00 00 17 C1 8E 33 EE 33 33 EE 33 33 EE 33 33 EE 33 33 BE 33 AC 9B AC 0D 0F FF
					//HBM_LV
					15 00 00 40 00 00 02 6F 1D
					39 00 00 40 00 00 03 C1 00 FF
					//APL_L/APL_H
					15 00 00 40 00 00 02 6F 20
					39 00 00 40 00 00 04 C1 0F 29 FF
					//DS_LV0_APL1
					15 00 00 40 00 00 02 6F 23
					39 00 00 40 00 00 15 C1 0E 33 EE 33 33 EE 33 33 EE 33 33 EE 33 33 BE 33 AC 9B AC 0D
					//DS_Lv1_Apl0
					15 00 00 40 00 00 02 6F 37
					39 00 00 40 00 00 15 C1 0F FF FF FF FF FF FF FF FF FF FF FF FF FF DF FF 27 AD 27 33
					//DS_Lv1_Apl1
					15 00 00 40 00 00 02 6F 4B
					39 00 00 40 00 00 15 C1 0E 33 EE 33 33 EE 33 33 EE 33 33 EE 33 33 BE 33 AC 9B AC 0D
					//DS_LV2_APL0
					15 00 00 40 00 00 02 6F 5F
					39 00 00 40 00 00 15 C1 0F FF FF FF FF FF FF FF FF FF FF FF FF FF FF FF FF FF FF FF
					//DS_LV2_APL1
					15 00 00 40 00 00 02 6F 73
					39 00 00 40 00 00 15 C1 0E 33 EE 33 33 EE 33 33 EE 33 33 EE 33 33 BE 33 AC 9B AC 0D
					//DS_DBV_TH
					39 00 00 40 00 00 11 BA 00 01 00 8A 00 8A 01 3C 01 3C 01 9D 01 9D 02 79
					15 00 00 40 00 00 02 6F 10
					39 00 00 40 00 00 11 BA 02 79 03 7D 03 7D 04 93 04 93 06 98 06 98 0A E2
					15 00 00 40 00 00 02 6F 20
					39 00 00 40 00 00 0D BA 0A E2 0D BB 0D BB 0F FE 0F FE 0F FF
					//GIR1.0
					15 00 00 40 00 00 02 6F 07
					15 00 00 00 00 00 02 51 00

					//Sleep out
					15 00 00 00 78 00 02 11 00
					//Display out
					15 00 00 00 00 00 02 29 00
					//scale up on
					39 00 00 40 00 00 05 2A 00 00 04 37
					39 00 00 40 00 00 05 2B 00 00 09 2F
					39 00 00 40 00 00 02 03 10
					39 00 00 40 00 00 02 8F 01
					//OSC Trim
					39 00 00 40 00 00 50 A9 02 01 C3 02 03 02 67 02 01 C3 08 08 67 02 01 C3 0B 0D 3F 51 FE 02 01 C3 0E 0F 3F 25 02 01 C3 10 10 A9 02 01 C3 11 13 3F 51 FE 02 01 C3 14 16 3F 25 A9 02 01 C3 23 25 3F 38 FC 02 01 C3 26 27 3F 2C 02 01 C3 28 28 A8 02 01 C3 29 2B 00 00 00
					//DSC setting lock
					39 00 00 40 00 00 07 A9 02 00 D8 0D 0D 42
					//Fcon setting 120Hz
					39 00 00 00 01 00 8F A9 01 00 2F 00 00 01 02 09 BD 00 00 05 02 08 B7 08 0F 00 C8 00 C8 02 58 02 58 02 08 B7 10 1F 03 E8 03 E8 03 E8 03 E8 05 DC 05 DC 07 D0 07 D0 02 08 B7 20 27 09 C4 09 C4 08 FC 08 FC 02 08 B7 28 2D 08 00 08 00 08 00 01 00 A2 00 20 07 02 01 DD 02 03 00 00 00 00 00 00 00 00 02 04 B5 02 03 00 03 00 00 00 00 00 00 01 00 9D 00 00 AA 01 00 8D 02 02 01 01 00 A3 00 0F 81 00 00 00 00 02 09 BD 00 00 04 00 00 00 00 00 01 00 A3 10 11 00 00
				];

				qcom,lm-split = <540 540>;
				qcom,mdss-dsc-slice-height = <16>;
				qcom,mdss-dsc-slice-width = <540>;
			};
			timing@fhd_sdc_90 {
				#include "dsi-panel-AE084-P-3-A0033-common.dtsi"
				#include "dsi-panel-AE084-P-3-A0033-common-effect.dtsi"
				cell-index = <5>;
				qcom,mdss-mdp-transfer-time-us = <9000>;
				qcom,mdss-dsi-panel-framerate = <90>;
				qcom,mdss-dsi-panel-clockrate = <1113600000>;
				qcom,mdss-dsi-panel-width = <1080>;
				qcom,mdss-dsi-panel-height = <2352>;

				qcom,mdss-dsi-h-front-porch = <16>;
				qcom,mdss-dsi-h-back-porch = <16>;
				qcom,mdss-dsi-h-pulse-width = <2>;
				qcom,mdss-dsi-v-back-porch = <28>;
				qcom,mdss-dsi-v-front-porch = <78>;
				qcom,mdss-dsi-v-pulse-width = <2>;
				qcom,mdss-dsi-h-sync-pulse = <0>;

				oplus,ofp-need-to-sync-data-in-aod-unlocking;
				oplus,ofp-aod-off-insert-black-frame = <1>;
				oplus,ofp-aod-off-black-frame-total-time = <42>;
				oplus,ofp-need-to-separate-backlight;
				oplus,ofp-backlight-on-period = <1>;

				qcom,mdss-dsi-timing-switch-command = [
					// OD setting
					39 00 00 40 00 00 47 A9 02 08 E0 00 00 40 02 08 E1 01 02 18 08 02 08 E2 01 02 1A 08 02 08 E1 0F 0F 1A 02 08 E1 10 10 08 02 08 E2 0F 0F 1A 02 08 E2 10 10 0B 02 08 E1 1D 1E 08 05 02 08 E2 1D 1E 0A 06 02 08 E1 2B 2B 09 02 08 E2 2B 2B 0B
					39 00 00 40 00 00 45 A9 02 08 E1 39 3A 04 04 02 08 E2 39 3A 04 04 02 08 E1 47 47 03 02 08 E2 47 47 03 02 08 E1 55 55 03 02 08 E2 55 55 03 02 08 E1 63 63 01 02 08 E2 63 63 01 02 08 E1 71 71 01 02 08 E2 71 71 01 02 08 E0 00 00 41
					//DSC setting unlock
					39 00 00 40 00 00 06 F0 55 AA 52 08 00
					39 00 00 40 00 00 02 6F 0D
					39 00 00 40 00 00 02 D8 40
					//DSC SET
					39 00 00 40 00 00 03 90 03 43
					39 00 00 40 00 00 13 91 AB A8 00 10 C2 00 02 68 01 BB 00 0A 06 67 04 C5 10 F0
					39 00 00 40 00 00 13 93 AB A8 00 10 C2 00 02 0E 01 84 00 07 06 67 06 5C 10 F0
					//Resolution binding
					39 00 00 40 00 00 05 2A 00 00 04 37
					39 00 00 40 00 00 05 2B 00 00 09 2F
					//DSC setting unlock
					39 00 00 40 00 00 06 F0 55 AA 52 08 00
					39 00 00 40 00 00 02 6F 0D
					39 00 00 40 00 00 02 D8 40
					//scale up on
					39 00 00 40 00 00 02 03 10
					39 00 00 40 00 00 02 8F 01
					//OSC Trim
					39 00 00 40 00 00 50 A9 02 01 C3 02 03 02 67 02 01 C3 08 08 67 02 01 C3 0B 0D 3F 51 FE 02 01 C3 0E 0F 3F 25 02 01 C3 10 10 A9 02 01 C3 11 13 3F 51 FE 02 01 C3 14 16 3F 25 A9 02 01 C3 23 25 3F 38 FC 02 01 C3 26 27 3F 2C 02 01 C3 28 28 A8 02 01 C3 29 2B 00 00 00
					//DSC setting lock
					39 00 00 40 00 00 06 F0 55 AA 52 08 00
					39 00 00 40 00 00 02 6F 0D
					39 00 00 40 00 00 02 D8 42
					//FPS setting 90Hz
					39 00 00 00 01 00 8F A9 01 00 2F 00 00 02 02 09 BD 00 00 05 02 08 B7 08 0F 00 C8 00 C8 02 58 02 58 02 08 B7 10 1F 03 E8 03 E8 03 E8 03 E8 05 DC 05 DC 07 D0 07 D0 02 08 B7 20 27 09 C4 09 C4 08 FC 08 FC 02 08 B7 28 2D 08 00 08 00 08 00 01 00 A2 00 20 07 02 01 DD 02 03 00 00 00 00 00 00 00 00 02 04 B5 02 03 00 09 00 00 00 00 00 00 01 00 9D 00 00 AA 01 00 8D 02 02 01 01 00 A3 00 0F 81 00 00 00 00 02 09 BD 00 00 04 00 00 00 00 00 01 00 A3 10 11 00 00
					39 00 00 00 00 00 06 F0 55 AA 52 08 FF
				];
				qcom,mdss-dsi-on-command = [
					//GPIO setting
					39 00 00 40 00 00 06 F0 55 AA 52 08 00
					39 00 00 40 00 00 05 BE 49 47 47 4A
					//APL BLK Setting
					39 00 00 40 00 00 06 F0 55 AA 52 08 00
					39 00 00 40 00 00 02 6F 78
					39 00 00 40 00 00 18 B0 11 00 2A 00 C2 01 DA 03 7C 05 B1 08 80 0B EE 0F FF 05 55 05 56 05 55
					//APL_BLK_R_NUM,APL_BLK_G_NUM,APL_BLK_B_NUM
					39 00 00 40 00 00 02 6F 6F
					39 00 00 40 00 00 07 B0 02 D0 05 A0 02 D0
					//Data Scale Ratio
					39 00 00 40 00 00 06 F0 55 AA 52 08 08
					39 00 00 40 00 00 17 C1 8E 33 EE 33 33 EE 33 33 EE 33 33 EE 33 33 BE 33 AC 9B AC 0D 0F FF
					39 00 00 40 00 00 02 6F 23
					39 00 00 40 00 00 15 C1 0E 33 EE 33 33 EE 33 33 EE 33 33 EE 33 33 BE 33 AC 9B AC 0D
					39 00 00 40 00 00 02 6F 37
					39 00 00 40 00 00 15 C1 0F FF FF FF FF FF FF FF FF FF FF FF FF FF DF FF 27 AD 27 33
					39 00 00 40 00 00 02 6F 4B
					39 00 00 40 00 00 15 C1 0E 33 EE 33 33 EE 33 33 EE 33 33 EE 33 33 BE 33 AC 9B AC 0D
					39 00 00 40 00 00 02 6F 5F
					39 00 00 40 00 00 15 C1 0F FF FF FF FF FF FF FF FF FF FF FF FF FF FF FF FF FF FF FF
					39 00 00 40 00 00 02 6F 73
					39 00 00 40 00 00 15 C1 0E 33 EE 33 33 EE 33 33 EE 33 33 EE 33 33 BE 33 AC 9B AC 0D
					//DS_DBV_TH
					39 00 00 40 00 00 11 BA 00 01 00 8A 00 8A 01 3C 01 3C 01 9D 01 9D 02 79
					39 00 00 40 00 00 02 6F 10
					39 00 00 40 00 00 11 BA 02 79 03 7D 03 7D 04 93 04 93 06 98 06 98 0A E2
					39 00 00 40 00 00 02 6F 20
					39 00 00 40 00 00 0D BA 0A E2 0D BB 0D BB 0F FE 0F FE 0F FF
					//APL_L/APL_H
					39 00 00 40 00 00 02 6F 20
					39 00 00 40 00 00 04 C1 0F 29 FF
					//HBM_LV0/1/2
					39 00 00 40 00 00 02 6F 1D
					39 00 00 40 00 00 04 C1 00 80 FF
					39 00 00 40 00 00 05 FF AA 55 A5 80
					//OSC Charge up 4uA
					39 00 00 40 00 00 02 6F 07
					39 00 00 40 00 00 02 F8 4D
					39 00 00 40 00 00 02 6F 23
					39 00 00 40 00 00 02 F8 4D
					//mtp_vgh_setting
					39 00 00 40 00 00 02 6F 04
					39 00 00 40 00 00 02 F2 1D
					//power on/off sequence
					39 00 00 40 00 00 02 6F 0A
					39 00 00 40 00 00 06 F6 70 70 70 70 70
					// stop_hclk_fskip & stop_hclk_vfp = 1
					39 00 00 40 00 00 05 FF AA 55 A5 81
					39 00 00 40 00 00 02 6F 0E
					39 00 00 40 00 00 02 F5 2B
					//bois clk,idle vfp clk off
					39 00 00 40 00 00 02 6F 0F
					39 00 00 40 00 00 02 F5 22
					// porch source setting
					39 00 00 40 00 00 02 6F 05
					39 00 00 40 00 00 03 FE 3C 3C
					//mipi timing optimize
					39 00 00 40 00 00 05 FF AA 55 A5 82
					39 00 00 40 00 00 02 6F 12
					39 00 00 40 00 00 03 F2 23 25
					//source status @ mtp status = hi-z
					39 00 00 40 00 00 06 F0 55 AA 52 08 00
					39 00 00 40 00 00 02 6F 04
					39 00 00 40 00 00 02 C2 32
					//Blue spot optimization
					39 00 00 40 00 00 06 F0 55 AA 52 08 00
					39 00 00 40 00 00 02 6F 31
					39 00 00 40 00 00 04 C0 00 22 00
					39 00 00 40 00 00 06 F0 55 AA 52 08 00
					39 00 00 40 00 00 02 6F 39
					39 00 00 40 00 00 04 C0 11 33 00
					//scaling up setting
					39 00 00 40 00 00 02 6F 0D
					39 00 00 40 00 00 02 D8 40
					39 00 00 40 00 00 02 C0 44
					//goa status @ mtp status = toggle
					39 00 00 40 00 00 06 F0 55 AA 52 08 01
					39 00 00 40 00 00 02 6F 08
					39 00 00 40 00 00 02 CA 00
					//keep command mode
					39 00 00 40 00 00 05 FF AA 55 A5 00
					39 00 00 40 00 00 06 F0 55 AA 52 00 00
					39 00 00 40 00 00 02 6F 02
					39 00 00 40 00 00 02 17 12
					39 00 00 40 00 00 02 35 08
					//BC Dimming OFF
					39 00 00 40 00 00 02 53 20
					//H_res = 1440 , V_res = 3136
					39 00 00 40 00 00 05 2a 00 00 05 9f
					39 00 00 40 00 00 05 2b 00 00 0C 3f
					//normal gma
					39 00 00 40 00 00 02 26 00
					//normal dbv
					39 00 00 40 00 00 03 51 00 00
					//idle dbv
					39 00 00 40 00 00 02 6F 04
					39 00 00 40 00 00 03 51 0D BB
					//LFCC LUT Table Sel
					39 00 00 40 00 00 02 68 00
					//md1,dpc temperature
					39 00 00 40 00 00 03 81 01 19
					//DSC setting unlock
					39 00 00 40 00 00 07 A9 02 00 D8 0D 0D 40
					//DSC SET
					39 00 00 40 00 00 03 90 03 43
					39 00 00 40 00 00 13 91 AB A8 00 10 C2 00 02 68 01 BB 00 0A 06 67 04 C5 10 F0
					39 00 00 00 00 00 13 93 AB A8 00 10 C2 00 02 0E 01 84 00 07 06 67 06 5C 10 F0
					//vdc & peak luminance
					39 00 00 40 00 00 03 5F 00 C0
					39 00 00 40 00 00 02 6F 07
					39 00 00 40 00 00 02 51 00
					//1nit rolling horizontal stripes
					39 00 00 40 00 00 06 F0 55 AA 52 08 00
					39 00 00 40 00 00 02 6F 62
					39 00 00 40 00 00 02 D5 0F
					39 00 00 40 00 00 02 6F 68
					39 00 00 40 00 00 02 D5 10
					//RND OFF
					39 00 00 40 00 00 06 F0 55 AA 52 08 07
					39 00 00 40 00 00 02 C0 06

					//OSC Trim
					39 00 00 40 00 00 06 F0 55 AA 52 08 01
					39 00 00 40 00 00 36 C3 99 29 02 87 19 00 29 00 87 19 00 3F 39 4B 3F 46 DD 3F 39 4B 3F 46 DD 3F 51 FE 3F 25 A9 3F 51 FE 3F 25 A9 3F 38 FC 3F 2C A8 11 00 00 00 00 00 77 00 AA 02 AA 02
					15 00 00 40 00 00 02 6F 04
					15 00 00 40 00 00 02 C3 19
					15 00 00 40 00 00 02 6F 09
					15 00 00 40 00 00 02 C3 19

					// OD setting
					39 00 00 40 00 00 06 F0 55 AA 52 08 08
					39 00 00 40 00 00 05 E0 41 01 01 01
					39 00 00 40 00 00 02 6F 06
					39 00 00 40 00 00 0E E0 80 00 21 32 43 54 65 76 87 98 99 99 99
					39 00 00 40 00 00 0F E1 03 18 08 0D 0E 0F 0F 10 12 14 14 17 1C 20
					39 00 00 40 00 00 0F E2 03 1A 08 0A 0C 0E 10 12 17 1A 1E 1F 20 21
					39 00 00 40 00 00 0F E3 00 00 00 00 00 00 00 00 00 00 00 00 00 00
					39 00 00 40 00 00 02 6F 0E
					39 00 00 40 00 00 0F E1 03 18 08 0A 0B 0B 0C 0D 0E 0E 12 14 17 20
					39 00 00 40 00 00 02 6F 0E
					39 00 00 40 00 00 0F E2 03 1A 0B 0F 10 10 11 12 13 13 14 15 17 19
					39 00 00 40 00 00 02 6F 0E
					39 00 00 40 00 00 0F E3 00 00 00 00 00 00 00 00 00 00 00 00 00 00
					39 00 00 40 00 00 02 6F 1C
					39 00 00 40 00 00 0F E1 02 08 05 0A 0A 0A 0A 0A 0A 0A 0B 0B 0D 0F
					39 00 00 40 00 00 02 6F 1C
					39 00 00 40 00 00 0F E2 02 0A 06 06 06 07 08 08 08 08 08 0A 0C 0D
					39 00 00 40 00 00 02 6F 1C
					39 00 00 40 00 00 0F E3 00 00 00 04 04 04 04 04 07 07 08 08 0C 0F
					39 00 00 40 00 00 02 6F 2A
					39 00 00 40 00 00 0F E1 01 09 04 05 05 06 07 08 08 0A 0B 0B 0E 13
					39 00 00 40 00 00 02 6F 2A
					39 00 00 40 00 00 0F E2 02 0B 04 08 08 08 08 08 08 08 0A 0B 0D 11
					39 00 00 40 00 00 02 6F 2A
					39 00 00 40 00 00 0F E3 00 00 00 03 03 03 03 03  03 07 09 0B 0D 12
					39 00 00 40 00 00 02 6F 38
					39 00 00 40 00 00 0F E1 01 04 04 05 05 05 05 05 06 09 0A 0B 0D 11
					39 00 00 40 00 00 02 6F 38
					39 00 00 40 00 00 0F E2 01 04 04 05 05 05 06 06 06 07 09 0B 0D 10
					39 00 00 40 00 00 02 6F 38
					39 00 00 40 00 00 0F E3 00 00 00 04 04 04 04 04 05 07 08 0A 0D 0F
					39 00 00 40 00 00 02 6F 46
					39 00 00 40 00 00 0F E1 01 03 03 05 05 05 05 05 06 08 09 0B 0C 0F
					39 00 00 40 00 00 02 6F 46
					39 00 00 40 00 00 0F E2 01 03 03 04 04 04 04 04 06 08 09 0A 0C 0F
					39 00 00 40 00 00 02 6F 46
					39 00 00 40 00 00 0F E3 00 00 00 03 03 03 03 03 06 08 09 0A 0C 10
					39 00 00 40 00 00 02 6F 54
					39 00 00 40 00 00 0F E1 01 03 03 04 04 04 04 04 06 08 09 0A 0B 0F
					39 00 00 40 00 00 02 6F 54
					39 00 00 40 00 00 0F E2 01 03 03 04 04 04 04 04 06 07 09 0A 0B 0E
					39 00 00 40 00 00 02 6F 54
					39 00 00 40 00 00 0F E3 00 00 00 02 02 03 03 04 05 07 09 0C 0E 12
					39 00 00 40 00 00 02 6F 62
					39 00 00 40 00 00 0F E1 01 01 02 03 03 04 04 04 06 07 08 0A 0C 0F
					39 00 00 40 00 00 02 6F 62
					39 00 00 40 00 00 0F E2 01 01 02 02 03 03 03 04 05 07 08 09 0A 0E
					39 00 00 40 00 00 02 6F 62
					39 00 00 40 00 00 0F E3 00 00 00 02 02 03 03 04 06 08 0A 0D 0E 12
					39 00 00 40 00 00 02 6F 70
					39 00 00 40 00 00 0F E1 01 01 02 02 03 03 03 04 05 07 09 0C 0D 11
					39 00 00 40 00 00 02 6F 70
					39 00 00 40 00 00 0F E2 01 01 02 02 03 03 03 04 05 07 09 0B 0C 0F
					39 00 00 40 00 00 02 6F 70
					39 00 00 40 00 00 0F E3 00 00 00 02 03 03 03 04 06 08 0B 0C 0C 0F

					//add uir config
					39 00 00 40 00 00 06 F0 55 AA 52 08 00
					15 00 00 40 00 00 02 6F 78
					39 00 00 40 00 00 18 B0 17 00 2A 00 C2 01 DA 03 7C 05 B1 08 80 0B EE 0F FF 05 55 05 56 05 55
					//APL_BLK_R_NUM,APL_BLK_G_NUM,APL_BLK_B_NUM
					15 00 00 40 00 00 02 6F 6F
					39 00 00 40 00 00 07 B0 02 D0 05 A0 02 D0
					//Data Scale Ratio
					39 00 00 40 00 00 06 F0 55 AA 52 08 08
					//DS_LV0_APL0
					39 00 00 40 00 00 17 C1 8E 33 EE 33 33 EE 33 33 EE 33 33 EE 33 33 BE 33 AC 9B AC 0D 0F FF
					//HBM_LV
					15 00 00 40 00 00 02 6F 1D
					39 00 00 40 00 00 03 C1 00 FF
					//APL_L/APL_H
					15 00 00 40 00 00 02 6F 20
					39 00 00 40 00 00 04 C1 0F 29 FF
					//DS_LV0_APL1
					15 00 00 40 00 00 02 6F 23
					39 00 00 40 00 00 15 C1 0E 33 EE 33 33 EE 33 33 EE 33 33 EE 33 33 BE 33 AC 9B AC 0D
					//DS_Lv1_Apl0
					15 00 00 40 00 00 02 6F 37
					39 00 00 40 00 00 15 C1 0F FF FF FF FF FF FF FF FF FF FF FF FF FF DF FF 27 AD 27 33
					//DS_Lv1_Apl1
					15 00 00 40 00 00 02 6F 4B
					39 00 00 40 00 00 15 C1 0E 33 EE 33 33 EE 33 33 EE 33 33 EE 33 33 BE 33 AC 9B AC 0D
					//DS_LV2_APL0
					15 00 00 40 00 00 02 6F 5F
					39 00 00 40 00 00 15 C1 0F FF FF FF FF FF FF FF FF FF FF FF FF FF FF FF FF FF FF FF
					//DS_LV2_APL1
					15 00 00 40 00 00 02 6F 73
					39 00 00 40 00 00 15 C1 0E 33 EE 33 33 EE 33 33 EE 33 33 EE 33 33 BE 33 AC 9B AC 0D
					//DS_DBV_TH
					39 00 00 40 00 00 11 BA 00 01 00 8A 00 8A 01 3C 01 3C 01 9D 01 9D 02 79
					15 00 00 40 00 00 02 6F 10
					39 00 00 40 00 00 11 BA 02 79 03 7D 03 7D 04 93 04 93 06 98 06 98 0A E2
					15 00 00 40 00 00 02 6F 20
					39 00 00 40 00 00 0D BA 0A E2 0D BB 0D BB 0F FE 0F FE 0F FF
					//GIR1.0
					15 00 00 40 00 00 02 6F 07
					15 00 00 00 00 00 02 51 00

					//Sleep out
					15 00 00 00 78 00 02 11 00
					//Display out
					15 00 00 00 00 00 02 29 00
					//scale up on
					39 00 00 40 00 00 05 2A 00 00 04 37
					39 00 00 40 00 00 05 2B 00 00 09 2F
					39 00 00 40 00 00 02 03 10
					39 00 00 40 00 00 02 8F 01
					//OSC Trim
					39 00 00 40 00 00 50 A9 02 01 C3 02 03 02 67 02 01 C3 08 08 67 02 01 C3 0B 0D 3F 51 FE 02 01 C3 0E 0F 3F 25 02 01 C3 10 10 A9 02 01 C3 11 13 3F 51 FE 02 01 C3 14 16 3F 25 A9 02 01 C3 23 25 3F 38 FC 02 01 C3 26 27 3F 2C 02 01 C3 28 28 A8 02 01 C3 29 2B 00 00 00
					//DSC setting lock
					39 00 00 40 00 00 07 A9 02 00 D8 0D 0D 42
					//FPS setting 90Hz
					39 00 00 00 01 00 8F A9 01 00 2F 00 00 02 02 09 BD 00 00 05 02 08 B7 08 0F 00 C8 00 C8 02 58 02 58 02 08 B7 10 1F 03 E8 03 E8 03 E8 03 E8 05 DC 05 DC 07 D0 07 D0 02 08 B7 20 27 09 C4 09 C4 08 FC 08 FC 02 08 B7 28 2D 08 00 08 00 08 00 01 00 A2 00 20 07 02 01 DD 02 03 00 00 00 00 00 00 00 00 02 04 B5 02 03 00 09 00 00 00 00 00 00 01 00 9D 00 00 AA 01 00 8D 02 02 01 01 00 A3 00 0F 81 00 00 00 00 02 09 BD 00 00 04 00 00 00 00 00 01 00 A3 10 11 00 00
				];

				qcom,lm-split = <540 540>;
				qcom,mdss-dsc-slice-height = <16>;
				qcom,mdss-dsc-slice-width = <540>;
			};
			timing@fhd_sdc_60 {
				#include "dsi-panel-AE084-P-3-A0033-common.dtsi"
				#include "dsi-panel-AE084-P-3-A0033-common-effect.dtsi"
				cell-index = <6>;
				qcom,mdss-mdp-transfer-time-us = <6800>;
				qcom,mdss-dsi-panel-framerate = <60>;
				qcom,mdss-dsi-panel-clockrate = <1113600000>;
				qcom,mdss-dsi-panel-width = <1080>;
				qcom,mdss-dsi-panel-height = <2352>;
				oplus,apollo-panel-async-bl-delay = <9000>;

				qcom,mdss-dsi-h-front-porch = <16>;
				qcom,mdss-dsi-h-back-porch = <16>;
				qcom,mdss-dsi-h-pulse-width = <2>;
				qcom,mdss-dsi-v-back-porch = <28>;
				qcom,mdss-dsi-v-front-porch = <78>;
				qcom,mdss-dsi-v-pulse-width = <2>;
				qcom,mdss-dsi-h-sync-pulse = <0>;

				oplus,ofp-need-to-sync-data-in-aod-unlocking;
				oplus,ofp-aod-off-insert-black-frame = <1>;
				oplus,ofp-aod-off-black-frame-total-time = <42>;
				oplus,ofp-need-to-separate-backlight;
				oplus,ofp-backlight-on-period = <1>;

				qcom,mdss-dsi-timing-switch-command = [
					// OD setting
					39 00 00 40 00 00 47 A9 02 08 E0 00 00 40 02 08 E1 01 02 12 08 02 08 E2 01 02 12 06 02 08 E1 0F 0F 0A 02 08 E1 10 10 04 02 08 E2 0F 0F 0A 02 08 E2 10 10 04 02 08 E1 1D 1E 06 04 02 08 E2 1D 1E 08 06 02 08 E1 2B 2B 04 02 08 E2 2B 2B 06
					39 00 00 40 00 00 45 A9 02 08 E1 39 3A 03 03 02 08 E2 39 3A 04 03 02 08 E1 47 47 02 02 08 E2 47 47 02 02 08 E1 55 55 02 02 08 E2 55 55 02 02 08 E1 63 63 01 02 08 E2 63 63 01 02 08 E1 71 71 01 02 08 E2 71 71 01 02 08 E0 00 00 41
					//DSC setting unlock
					39 00 00 40 00 00 06 F0 55 AA 52 08 00
					39 00 00 40 00 00 02 6F 0D
					39 00 00 40 00 00 02 D8 40
					//DSC SET
					39 00 00 40 00 00 03 90 03 43
					39 00 00 40 00 00 13 91 AB A8 00 10 C2 00 02 68 01 BB 00 0A 06 67 04 C5 10 F0
					39 00 00 40 00 00 13 93 AB A8 00 10 C2 00 02 0E 01 84 00 07 06 67 06 5C 10 F0
					//Resolution binding
					39 00 00 40 00 00 05 2A 00 00 04 37
					39 00 00 40 00 00 05 2B 00 00 09 2F
					//DSC setting unlock
					39 00 00 40 00 00 06 F0 55 AA 52 08 00
					39 00 00 40 00 00 02 6F 0D
					39 00 00 40 00 00 02 D8 40
					//scale up on
					39 00 00 40 00 00 02 03 10
					39 00 00 40 00 00 02 8F 01
					//OSC Trim
					39 00 00 40 00 00 50 A9 02 01 C3 02 03 02 67 02 01 C3 08 08 67 02 01 C3 0B 0D 3F 51 FE 02 01 C3 0E 0F 3F 25 02 01 C3 10 10 A9 02 01 C3 11 13 3F 51 FE 02 01 C3 14 16 3F 25 A9 02 01 C3 23 25 3F 38 FC 02 01 C3 26 27 3F 2C 02 01 C3 28 28 A8 02 01 C3 29 2B 00 00 00
					//DSC setting lock
					39 00 00 40 00 00 06 F0 55 AA 52 08 00
					39 00 00 40 00 00 02 6F 0D
					39 00 00 40 00 00 02 D8 42
					//FPS setting 60Hz
					39 00 00 00 01 00 8F A9 01 00 2F 00 00 03 02 09 BD 00 00 05 02 08 B7 08 0F 00 C8 00 C8 02 58 02 58 02 08 B7 10 1F 03 E8 03 E8 03 E8 03 E8 05 DC 05 DC 07 D0 07 D0 02 08 B7 20 27 09 C4 09 C4 08 FC 08 FC 02 08 B7 28 2D 08 00 08 00 08 00 01 00 A2 00 20 07 02 01 DD 02 03 00 00 00 00 00 00 00 00 02 04 B5 02 03 00 03 00 00 00 00 00 00 01 00 9D 00 00 AA 01 00 8D 02 02 01 01 00 A3 00 0F 81 00 00 00 00 02 09 BD 00 00 04 00 00 00 00 00 01 00 A3 10 11 00 00
					39 00 00 00 00 00 06 F0 55 AA 52 08 FF
				];
				qcom,mdss-dsi-on-command = [
					//GPIO setting
					39 00 00 40 00 00 06 F0 55 AA 52 08 00
					39 00 00 40 00 00 05 BE 49 47 47 4A
					//APL BLK Setting
					39 00 00 40 00 00 06 F0 55 AA 52 08 00
					39 00 00 40 00 00 02 6F 78
					39 00 00 40 00 00 18 B0 11 00 2A 00 C2 01 DA 03 7C 05 B1 08 80 0B EE 0F FF 05 55 05 56 05 55
					//APL_BLK_R_NUM,APL_BLK_G_NUM,APL_BLK_B_NUM
					39 00 00 40 00 00 02 6F 6F
					39 00 00 40 00 00 07 B0 02 D0 05 A0 02 D0
					//Data Scale Ratio
					39 00 00 40 00 00 06 F0 55 AA 52 08 08
					39 00 00 40 00 00 17 C1 8E 33 EE 33 33 EE 33 33 EE 33 33 EE 33 33 BE 33 AC 9B AC 0D 0F FF
					39 00 00 40 00 00 02 6F 23
					39 00 00 40 00 00 15 C1 0E 33 EE 33 33 EE 33 33 EE 33 33 EE 33 33 BE 33 AC 9B AC 0D
					39 00 00 40 00 00 02 6F 37
					39 00 00 40 00 00 15 C1 0F FF FF FF FF FF FF FF FF FF FF FF FF FF DF FF 27 AD 27 33
					39 00 00 40 00 00 02 6F 4B
					39 00 00 40 00 00 15 C1 0E 33 EE 33 33 EE 33 33 EE 33 33 EE 33 33 BE 33 AC 9B AC 0D
					39 00 00 40 00 00 02 6F 5F
					39 00 00 40 00 00 15 C1 0F FF FF FF FF FF FF FF FF FF FF FF FF FF FF FF FF FF FF FF
					39 00 00 40 00 00 02 6F 73
					39 00 00 40 00 00 15 C1 0E 33 EE 33 33 EE 33 33 EE 33 33 EE 33 33 BE 33 AC 9B AC 0D
					//DS_DBV_TH
					39 00 00 40 00 00 11 BA 00 01 00 8A 00 8A 01 3C 01 3C 01 9D 01 9D 02 79
					39 00 00 40 00 00 02 6F 10
					39 00 00 40 00 00 11 BA 02 79 03 7D 03 7D 04 93 04 93 06 98 06 98 0A E2
					39 00 00 40 00 00 02 6F 20
					39 00 00 40 00 00 0D BA 0A E2 0D BB 0D BB 0F FE 0F FE 0F FF
					//APL_L/APL_H
					39 00 00 40 00 00 02 6F 20
					39 00 00 40 00 00 04 C1 0F 29 FF
					//HBM_LV0/1/2
					39 00 00 40 00 00 02 6F 1D
					39 00 00 40 00 00 04 C1 00 80 FF
					39 00 00 40 00 00 05 FF AA 55 A5 80
					//OSC Charge up 4uA
					39 00 00 40 00 00 02 6F 07
					39 00 00 40 00 00 02 F8 4D
					39 00 00 40 00 00 02 6F 23
					39 00 00 40 00 00 02 F8 4D
					//mtp_vgh_setting
					39 00 00 40 00 00 02 6F 04
					39 00 00 40 00 00 02 F2 1D
					//power on/off sequence
					39 00 00 40 00 00 02 6F 0A
					39 00 00 40 00 00 06 F6 70 70 70 70 70
					// stop_hclk_fskip & stop_hclk_vfp = 1
					39 00 00 40 00 00 05 FF AA 55 A5 81
					39 00 00 40 00 00 02 6F 0E
					39 00 00 40 00 00 02 F5 2B
					//bois clk,idle vfp clk off
					39 00 00 40 00 00 02 6F 0F
					39 00 00 40 00 00 02 F5 22
					// porch source setting
					39 00 00 40 00 00 02 6F 05
					39 00 00 40 00 00 03 FE 3C 3C
					//mipi timing optimize
					39 00 00 40 00 00 05 FF AA 55 A5 82
					39 00 00 40 00 00 02 6F 12
					39 00 00 40 00 00 03 F2 23 25
					//source status @ mtp status = hi-z
					39 00 00 40 00 00 06 F0 55 AA 52 08 00
					39 00 00 40 00 00 02 6F 04
					39 00 00 40 00 00 02 C2 32
					//Blue spot optimization
					39 00 00 40 00 00 06 F0 55 AA 52 08 00
					39 00 00 40 00 00 02 6F 31
					39 00 00 40 00 00 04 C0 00 22 00
					39 00 00 40 00 00 06 F0 55 AA 52 08 00
					39 00 00 40 00 00 02 6F 39
					39 00 00 40 00 00 04 C0 11 33 00
					//scaling up setting
					39 00 00 40 00 00 02 6F 0D
					39 00 00 40 00 00 02 D8 40
					39 00 00 40 00 00 02 C0 44
					//goa status @ mtp status = toggle
					39 00 00 40 00 00 06 F0 55 AA 52 08 01
					39 00 00 40 00 00 02 6F 08
					39 00 00 40 00 00 02 CA 00
					//keep command mode
					39 00 00 40 00 00 05 FF AA 55 A5 00
					39 00 00 40 00 00 06 F0 55 AA 52 00 00
					39 00 00 40 00 00 02 6F 02
					39 00 00 40 00 00 02 17 12
					39 00 00 40 00 00 02 35 08
					//BC Dimming OFF
					39 00 00 40 00 00 02 53 20
					//H_res = 1440 , V_res = 3136
					39 00 00 40 00 00 05 2a 00 00 05 9f
					39 00 00 40 00 00 05 2b 00 00 0C 3f
					//normal gma
					39 00 00 40 00 00 02 26 00
					//normal dbv
					39 00 00 40 00 00 03 51 00 00
					//idle dbv
					39 00 00 40 00 00 02 6F 04
					39 00 00 40 00 00 03 51 0D BB
					//LFCC LUT Table Sel
					39 00 00 40 00 00 02 68 00
					//md1,dpc temperature
					39 00 00 40 00 00 03 81 01 19
					//DSC setting unlock
					39 00 00 40 00 00 07 A9 02 00 D8 0D 0D 40
					//DSC SET
					39 00 00 40 00 00 03 90 03 43
					39 00 00 40 00 00 13 91 AB A8 00 10 C2 00 02 68 01 BB 00 0A 06 67 04 C5 10 F0
					39 00 00 00 00 00 13 93 AB A8 00 10 C2 00 02 0E 01 84 00 07 06 67 06 5C 10 F0
					//vdc & peak luminance
					39 00 00 40 00 00 03 5F 00 C0
					39 00 00 40 00 00 02 6F 07
					39 00 00 40 00 00 02 51 00
					//1nit rolling horizontal stripes
					39 00 00 40 00 00 06 F0 55 AA 52 08 00
					39 00 00 40 00 00 02 6F 62
					39 00 00 40 00 00 02 D5 0F
					39 00 00 40 00 00 02 6F 68
					39 00 00 40 00 00 02 D5 10
					//RND OFF
					39 00 00 40 00 00 06 F0 55 AA 52 08 07
					39 00 00 40 00 00 02 C0 06

					//OSC Trim
					39 00 00 40 00 00 06 F0 55 AA 52 08 01
					39 00 00 40 00 00 36 C3 99 29 02 87 19 00 29 00 87 19 00 3F 39 4B 3F 46 DD 3F 39 4B 3F 46 DD 3F 51 FE 3F 25 A9 3F 51 FE 3F 25 A9 3F 38 FC 3F 2C A8 11 00 00 00 00 00 77 00 AA 02 AA 02
					15 00 00 40 00 00 02 6F 04
					15 00 00 40 00 00 02 C3 19
					15 00 00 40 00 00 02 6F 09
					15 00 00 40 00 00 02 C3 19

					// OD setting
					39 00 00 40 00 00 06 F0 55 AA 52 08 08
					39 00 00 40 00 00 05 E0 41 01 01 01
					39 00 00 40 00 00 02 6F 06
					39 00 00 40 00 00 0E E0 80 00 21 32 43 54 65 76 87 98 99 99 99
					39 00 00 40 00 00 0F E1 03 12 08 0D 0E 0F 0F 10 12 14 14 17 1C 20
					39 00 00 40 00 00 0F E2 03 12 06 0A 0C 0E 10 12 17 1A 1E 1F 20 21
					39 00 00 40 00 00 0F E3 00 00 00 00 00 00 00 00 00 00 00 00 00 00
					39 00 00 40 00 00 02 6F 0E
					39 00 00 40 00 00 0F E1 03 0A 04 0A 0B 0B 0C 0D 0E 0E 12 14 17 20
					39 00 00 40 00 00 02 6F 0E
					39 00 00 40 00 00 0F E2 03 0A 04 0F 10 10 11 12 13 13 14 15 17 19
					39 00 00 40 00 00 02 6F 0E
					39 00 00 40 00 00 0F E3 00 00 00 00 00 00 00 00 00 00 00 00 00 00
					39 00 00 40 00 00 02 6F 1C
					39 00 00 40 00 00 0F E1 02 06 04 0A 0A 0A 0A 0A 0A 0A 0B 0B 0D 0F
					39 00 00 40 00 00 02 6F 1C
					39 00 00 40 00 00 0F E2 02 08 06 06 06 07 08 08 08 08 08 0A 0C 0D
					39 00 00 40 00 00 02 6F 1C
					39 00 00 40 00 00 0F E3 00 00 00 04 04 04 04 04 07 07 08 08 0C 0F
					39 00 00 40 00 00 02 6F 2A
					39 00 00 40 00 00 0F E1 01 04 04 05 05 06 07 08 08 0A 0B 0B 0E 13
					39 00 00 40 00 00 02 6F 2A
					39 00 00 40 00 00 0F E2 02 06 04 08 08 08 08 08 08 08 0A 0B 0D 11
					39 00 00 40 00 00 02 6F 2A
					39 00 00 40 00 00 0F E3 00 00 00 03 03 03 03 03  03 07 09 0B 0D 12
					39 00 00 40 00 00 02 6F 38
					39 00 00 40 00 00 0F E1 01 03 03 05 05 05 05 05 06 09 0A 0B 0D 11
					39 00 00 40 00 00 02 6F 38
					39 00 00 40 00 00 0F E2 01 04 03 05 05 05 06 06 06 07 09 0B 0D 10
					39 00 00 40 00 00 02 6F 38
					39 00 00 40 00 00 0F E3 00 00 00 04 04 04 04 04 05 07 08 0A 0D 0F
					39 00 00 40 00 00 02 6F 46
					39 00 00 40 00 00 0F E1 01 02 03 05 05 05 05 05 06 08 09 0B 0C 0F
					39 00 00 40 00 00 02 6F 46
					39 00 00 40 00 00 0F E2 01 02 03 04 04 04 04 04 06 08 09 0A 0C 0F
					39 00 00 40 00 00 02 6F 46
					39 00 00 40 00 00 0F E3 00 00 00 03 03 03 03 03 06 08 09 0A 0C 10
					39 00 00 40 00 00 02 6F 54
					39 00 00 40 00 00 0F E1 01 02 03 04 04 04 04 04 06 08 09 0A 0B 0F
					39 00 00 40 00 00 02 6F 54
					39 00 00 40 00 00 0F E2 01 02 03 04 04 04 04 04 06 07 09 0A 0B 0E
					39 00 00 40 00 00 02 6F 54
					39 00 00 40 00 00 0F E3 00 00 00 02 02 03 03 04 05 07 09 0C 0E 12
					39 00 00 40 00 00 02 6F 62
					39 00 00 40 00 00 0F E1 01 01 02 03 03 04 04 04 06 07 08 0A 0C 0F
					39 00 00 40 00 00 02 6F 62
					39 00 00 40 00 00 0F E2 01 01 02 02 03 03 03 04 05 07 08 09 0A 0E
					39 00 00 40 00 00 02 6F 62
					39 00 00 40 00 00 0F E3 00 00 00 02 02 03 03 04 06 08 0A 0D 0E 12
					39 00 00 40 00 00 02 6F 70
					39 00 00 40 00 00 0F E1 01 01 02 02 03 03 03 04 05 07 09 0C 0D 11
					39 00 00 40 00 00 02 6F 70
					39 00 00 40 00 00 0F E2 01 01 02 02 03 03 03 04 05 07 09 0B 0C 0F
					39 00 00 40 00 00 02 6F 70
					39 00 00 40 00 00 0F E3 00 00 00 02 03 03 03 04 06 08 0B 0C 0C 0F

					//add uir config
					39 00 00 40 00 00 06 F0 55 AA 52 08 00
					15 00 00 40 00 00 02 6F 78
					39 00 00 40 00 00 18 B0 17 00 2A 00 C2 01 DA 03 7C 05 B1 08 80 0B EE 0F FF 05 55 05 56 05 55
					//APL_BLK_R_NUM,APL_BLK_G_NUM,APL_BLK_B_NUM
					15 00 00 40 00 00 02 6F 6F
					39 00 00 40 00 00 07 B0 02 D0 05 A0 02 D0
					//Data Scale Ratio
					39 00 00 40 00 00 06 F0 55 AA 52 08 08
					//DS_LV0_APL0
					39 00 00 40 00 00 17 C1 8E 33 EE 33 33 EE 33 33 EE 33 33 EE 33 33 BE 33 AC 9B AC 0D 0F FF
					//HBM_LV
					15 00 00 40 00 00 02 6F 1D
					39 00 00 40 00 00 03 C1 00 FF
					//APL_L/APL_H
					15 00 00 40 00 00 02 6F 20
					39 00 00 40 00 00 04 C1 0F 29 FF
					//DS_LV0_APL1
					15 00 00 40 00 00 02 6F 23
					39 00 00 40 00 00 15 C1 0E 33 EE 33 33 EE 33 33 EE 33 33 EE 33 33 BE 33 AC 9B AC 0D
					//DS_Lv1_Apl0
					15 00 00 40 00 00 02 6F 37
					39 00 00 40 00 00 15 C1 0F FF FF FF FF FF FF FF FF FF FF FF FF FF DF FF 27 AD 27 33
					//DS_Lv1_Apl1
					15 00 00 40 00 00 02 6F 4B
					39 00 00 40 00 00 15 C1 0E 33 EE 33 33 EE 33 33 EE 33 33 EE 33 33 BE 33 AC 9B AC 0D
					//DS_LV2_APL0
					15 00 00 40 00 00 02 6F 5F
					39 00 00 40 00 00 15 C1 0F FF FF FF FF FF FF FF FF FF FF FF FF FF FF FF FF FF FF FF
					//DS_LV2_APL1
					15 00 00 40 00 00 02 6F 73
					39 00 00 40 00 00 15 C1 0E 33 EE 33 33 EE 33 33 EE 33 33 EE 33 33 BE 33 AC 9B AC 0D
					//DS_DBV_TH
					39 00 00 40 00 00 11 BA 00 01 00 8A 00 8A 01 3C 01 3C 01 9D 01 9D 02 79
					15 00 00 40 00 00 02 6F 10
					39 00 00 40 00 00 11 BA 02 79 03 7D 03 7D 04 93 04 93 06 98 06 98 0A E2
					15 00 00 40 00 00 02 6F 20
					39 00 00 40 00 00 0D BA 0A E2 0D BB 0D BB 0F FE 0F FE 0F FF
					//GIR1.0
					15 00 00 40 00 00 02 6F 07
					15 00 00 00 00 00 02 51 00

					//Sleep out
					15 00 00 00 78 00 02 11 00
					//Display out
					15 00 00 00 00 00 02 29 00
					//scale up on
					39 00 00 40 00 00 05 2A 00 00 04 37
					39 00 00 40 00 00 05 2B 00 00 09 2F
					39 00 00 40 00 00 02 03 10
					39 00 00 40 00 00 02 8F 01
					//OSC Trim
					39 00 00 40 00 00 50 A9 02 01 C3 02 03 02 67 02 01 C3 08 08 67 02 01 C3 0B 0D 3F 51 FE 02 01 C3 0E 0F 3F 25 02 01 C3 10 10 A9 02 01 C3 11 13 3F 51 FE 02 01 C3 14 16 3F 25 A9 02 01 C3 23 25 3F 38 FC 02 01 C3 26 27 3F 2C 02 01 C3 28 28 A8 02 01 C3 29 2B 00 00 00
					//DSC setting lock
					39 00 00 40 00 00 07 A9 02 00 D8 0D 0D 42
					//FPS setting 60Hz
					39 00 00 00 01 00 8F A9 01 00 2F 00 00 03 02 09 BD 00 00 05 02 08 B7 08 0F 00 C8 00 C8 02 58 02 58 02 08 B7 10 1F 03 E8 03 E8 03 E8 03 E8 05 DC 05 DC 07 D0 07 D0 02 08 B7 20 27 09 C4 09 C4 08 FC 08 FC 02 08 B7 28 2D 08 00 08 00 08 00 01 00 A2 00 20 07 02 01 DD 02 03 00 00 00 00 00 00 00 00 02 04 B5 02 03 00 03 00 00 00 00 00 00 01 00 9D 00 00 AA 01 00 8D 02 02 01 01 00 A3 00 0F 81 00 00 00 00 02 09 BD 00 00 04 00 00 00 00 00 01 00 A3 10 11 00 00
				];

				qcom,lm-split = <540 540>;
				qcom,mdss-dsc-slice-height = <16>;
				qcom,mdss-dsc-slice-width = <540>;
			};
			timing@fhd_sdc_144 {
				#include "dsi-panel-AE084-P-3-A0033-common.dtsi"
				#include "dsi-panel-AE084-P-3-A0033-common-effect.dtsi"
				cell-index = <7>;
				qcom,mdss-mdp-transfer-time-us = <6800>;
				qcom,mdss-dsi-panel-framerate = <144>;
				qcom,mdss-dsi-panel-clockrate = <1113600000>;
				qcom,mdss-dsi-panel-width = <1080>;
				qcom,mdss-dsi-panel-height = <2352>;

				qcom,mdss-dsi-h-front-porch = <16>;
				qcom,mdss-dsi-h-back-porch = <16>;
				qcom,mdss-dsi-h-pulse-width = <2>;
				qcom,mdss-dsi-v-back-porch = <28>;
				qcom,mdss-dsi-v-front-porch = <78>;
				qcom,mdss-dsi-v-pulse-width = <2>;
				qcom,mdss-dsi-h-sync-pulse = <0>;

				oplus,ofp-need-to-sync-data-in-aod-unlocking;
				oplus,ofp-aod-off-insert-black-frame = <1>;
				oplus,ofp-aod-off-black-frame-total-time = <42>;
				oplus,ofp-need-to-separate-backlight;
				oplus,ofp-backlight-on-period = <1>;

				qcom,mdss-dsi-timing-switch-command = [
					// OD setting
					39 00 00 40 00 00 47 A9 02 08 E0 00 00 40 02 08 E1 01 02 20 04 02 08 E2 01 02 20 04 02 08 E1 0F 0F 16 02 08 E1 10 10 08 02 08 E2 0F 0F 1C 02 08 E2 10 10 0A 02 08 E1 1D 1E 0D 04 02 08 E2 1D 1E 12 06 02 08 E1 2B 2B 0A 02 08 E2 2B 2B 12
					39 00 00 40 00 00 45 A9 02 08 E1 39 3A 08 04 02 08 E2 39 3A 0A 04 02 08 E1 47 47 06 02 08 E2 47 47 06 02 08 E1 55 55 06 02 08 E2 55 55 06 02 08 E1 63 63 02 02 08 E2 63 63 02 02 08 E1 71 71 02 02 08 E2 71 71 02 02 08 E0 00 00 41
					//DSC setting unlock
					39 00 00 40 00 00 06 F0 55 AA 52 08 00
					39 00 00 40 00 00 02 6F 0D
					39 00 00 40 00 00 02 D8 40
					//DSC SET
					39 00 00 40 00 00 03 90 03 43
					39 00 00 40 00 00 13 91 AB A8 00 10 C2 00 02 68 01 BB 00 0A 06 67 04 C5 10 F0
					39 00 00 40 00 00 13 93 AB A8 00 10 C2 00 02 0E 01 84 00 07 06 67 06 5C 10 F0
					//Resolution binding
					39 00 00 40 00 00 05 2A 00 00 04 37
					39 00 00 40 00 00 05 2B 00 00 09 2F
					//DSC setting unlock
					39 00 00 40 00 00 06 F0 55 AA 52 08 00
					39 00 00 40 00 00 02 6F 0D
					39 00 00 40 00 00 02 D8 40
					//scale up on
					39 00 00 40 00 00 02 03 10
					39 00 00 40 00 00 02 8F 01
					//OSC Trim
					39 00 00 40 00 00 50 A9 02 01 C3 02 03 02 67 02 01 C3 08 08 67 02 01 C3 0B 0D 3F 51 FE 02 01 C3 0E 0F 3F 25 02 01 C3 10 10 A9 02 01 C3 11 13 3F 51 FE 02 01 C3 14 16 3F 25 A9 02 01 C3 23 25 3F 38 FC 02 01 C3 26 27 3F 2C 02 01 C3 28 28 A8 02 01 C3 29 2B 00 00 00
					//DSC setting lock
					39 00 00 40 00 00 06 F0 55 AA 52 08 00
					39 00 00 40 00 00 02 6F 0D
					39 00 00 40 00 00 02 D8 42
					//FPS setting 144Hz
					39 00 00 00 01 00 8F A9 01 00 2F 00 00 00 02 09 BD 00 00 05 02 08 B7 08 0F 02 58 02 58 04 B0 04 B0 02 08 B7 10 1F 07 6C 07 6C 07 08 07 08 0A 28 0A 28 0B B8 0B B8 02 08 B7 20 27 0D AC 0D AC 0C E4 0C E4 02 08 B7 28 2D 0B B8 0B B8 0B B8 01 00 A2 00 20 07 02 01 DD 02 03 05 BE 00 00 00 00 00 00 02 04 B5 02 03 00 0C 00 00 00 00 00 00 01 00 9D 00 00 AA 01 00 8D 02 02 01 01 00 A3 00 0F 81 00 00 00 00 02 09 BD 00 00 04 00 00 00 00 00 01 00 A3 10 11 00 00
					39 00 00 00 00 00 06 F0 55 AA 52 08 FF
				];
				qcom,mdss-dsi-on-command = [
					//GPIO setting
					39 00 00 40 00 00 06 F0 55 AA 52 08 00
					39 00 00 40 00 00 05 BE 49 47 47 4A
					//APL BLK Setting
					39 00 00 40 00 00 06 F0 55 AA 52 08 00
					39 00 00 40 00 00 02 6F 78
					39 00 00 40 00 00 18 B0 11 00 2A 00 C2 01 DA 03 7C 05 B1 08 80 0B EE 0F FF 05 55 05 56 05 55
					//APL_BLK_R_NUM,APL_BLK_G_NUM,APL_BLK_B_NUM
					39 00 00 40 00 00 02 6F 6F
					39 00 00 40 00 00 07 B0 02 D0 05 A0 02 D0
					//Data Scale Ratio
					39 00 00 40 00 00 06 F0 55 AA 52 08 08
					39 00 00 40 00 00 17 C1 8E 33 EE 33 33 EE 33 33 EE 33 33 EE 33 33 BE 33 AC 9B AC 0D 0F FF
					39 00 00 40 00 00 02 6F 23
					39 00 00 40 00 00 15 C1 0E 33 EE 33 33 EE 33 33 EE 33 33 EE 33 33 BE 33 AC 9B AC 0D
					39 00 00 40 00 00 02 6F 37
					39 00 00 40 00 00 15 C1 0F FF FF FF FF FF FF FF FF FF FF FF FF FF DF FF 27 AD 27 33
					39 00 00 40 00 00 02 6F 4B
					39 00 00 40 00 00 15 C1 0E 33 EE 33 33 EE 33 33 EE 33 33 EE 33 33 BE 33 AC 9B AC 0D
					39 00 00 40 00 00 02 6F 5F
					39 00 00 40 00 00 15 C1 0F FF FF FF FF FF FF FF FF FF FF FF FF FF FF FF FF FF FF FF
					39 00 00 40 00 00 02 6F 73
					39 00 00 40 00 00 15 C1 0E 33 EE 33 33 EE 33 33 EE 33 33 EE 33 33 BE 33 AC 9B AC 0D
					//DS_DBV_TH
					39 00 00 40 00 00 11 BA 00 01 00 8A 00 8A 01 3C 01 3C 01 9D 01 9D 02 79
					39 00 00 40 00 00 02 6F 10
					39 00 00 40 00 00 11 BA 02 79 03 7D 03 7D 04 93 04 93 06 98 06 98 0A E2
					39 00 00 40 00 00 02 6F 20
					39 00 00 40 00 00 0D BA 0A E2 0D BB 0D BB 0F FE 0F FE 0F FF
					//APL_L/APL_H
					39 00 00 40 00 00 02 6F 20
					39 00 00 40 00 00 04 C1 0F 29 FF
					//HBM_LV0/1/2
					39 00 00 40 00 00 02 6F 1D
					39 00 00 40 00 00 04 C1 00 80 FF
					39 00 00 40 00 00 05 FF AA 55 A5 80
					//OSC Charge up 4uA
					39 00 00 40 00 00 02 6F 07
					39 00 00 40 00 00 02 F8 4D
					39 00 00 40 00 00 02 6F 23
					39 00 00 40 00 00 02 F8 4D
					//mtp_vgh_setting
					39 00 00 40 00 00 02 6F 04
					39 00 00 40 00 00 02 F2 1D
					//power on/off sequence
					39 00 00 40 00 00 02 6F 0A
					39 00 00 40 00 00 06 F6 70 70 70 70 70
					// stop_hclk_fskip & stop_hclk_vfp = 1
					39 00 00 40 00 00 05 FF AA 55 A5 81
					39 00 00 40 00 00 02 6F 0E
					39 00 00 40 00 00 02 F5 2B
					//bois clk,idle vfp clk off
					39 00 00 40 00 00 02 6F 0F
					39 00 00 40 00 00 02 F5 22
					// porch source setting
					39 00 00 40 00 00 02 6F 05
					39 00 00 40 00 00 03 FE 3C 3C
					//mipi timing optimize
					39 00 00 40 00 00 05 FF AA 55 A5 82
					39 00 00 40 00 00 02 6F 12
					39 00 00 40 00 00 03 F2 23 25
					//source status @ mtp status = hi-z
					39 00 00 40 00 00 06 F0 55 AA 52 08 00
					39 00 00 40 00 00 02 6F 04
					39 00 00 40 00 00 02 C2 32
					//Blue spot optimization
					39 00 00 40 00 00 06 F0 55 AA 52 08 00
					39 00 00 40 00 00 02 6F 31
					39 00 00 40 00 00 04 C0 00 22 00
					39 00 00 40 00 00 06 F0 55 AA 52 08 00
					39 00 00 40 00 00 02 6F 39
					39 00 00 40 00 00 04 C0 11 33 00
					//scaling up setting
					39 00 00 40 00 00 02 6F 0D
					39 00 00 40 00 00 02 D8 40
					39 00 00 40 00 00 02 C0 44
					//goa status @ mtp status = toggle
					39 00 00 40 00 00 06 F0 55 AA 52 08 01
					39 00 00 40 00 00 02 6F 08
					39 00 00 40 00 00 02 CA 00
					//keep command mode
					39 00 00 40 00 00 05 FF AA 55 A5 00
					39 00 00 40 00 00 06 F0 55 AA 52 00 00
					39 00 00 40 00 00 02 6F 02
					39 00 00 40 00 00 02 17 12
					39 00 00 40 00 00 02 35 08
					//BC Dimming OFF
					39 00 00 40 00 00 02 53 20
					//H_res = 1440 , V_res = 3136
					39 00 00 40 00 00 05 2a 00 00 05 9f
					39 00 00 40 00 00 05 2b 00 00 0C 3f
					//normal gma
					39 00 00 40 00 00 02 26 00
					//normal dbv
					39 00 00 40 00 00 03 51 00 00
					//idle dbv
					39 00 00 40 00 00 02 6F 04
					39 00 00 40 00 00 03 51 0D BB
					//LFCC LUT Table Sel
					39 00 00 40 00 00 02 68 00
					//md1,dpc temperature
					39 00 00 40 00 00 03 81 01 19
					//DSC setting unlock
					39 00 00 40 00 00 07 A9 02 00 D8 0D 0D 40
					//DSC SET
					39 00 00 40 00 00 03 90 03 43
					39 00 00 40 00 00 13 91 AB A8 00 10 C2 00 02 68 01 BB 00 0A 06 67 04 C5 10 F0
					39 00 00 00 00 00 13 93 AB A8 00 10 C2 00 02 0E 01 84 00 07 06 67 06 5C 10 F0
					//vdc & peak luminance
					39 00 00 40 00 00 03 5F 00 C0
					39 00 00 40 00 00 02 6F 07
					39 00 00 40 00 00 02 51 00
					//1nit rolling horizontal stripes
					39 00 00 40 00 00 06 F0 55 AA 52 08 00
					39 00 00 40 00 00 02 6F 62
					39 00 00 40 00 00 02 D5 0F
					39 00 00 40 00 00 02 6F 68
					39 00 00 40 00 00 02 D5 10
					//RND OFF
					39 00 00 40 00 00 06 F0 55 AA 52 08 07
					39 00 00 40 00 00 02 C0 06

					//OSC Trim
					39 00 00 40 00 00 06 F0 55 AA 52 08 01
					39 00 00 40 00 00 36 C3 99 29 02 87 19 00 29 00 87 19 00 3F 39 4B 3F 46 DD 3F 39 4B 3F 46 DD 3F 51 FE 3F 25 A9 3F 51 FE 3F 25 A9 3F 38 FC 3F 2C A8 11 00 00 00 00 00 77 00 AA 02 AA 02
					15 00 00 40 00 00 02 6F 04
					15 00 00 40 00 00 02 C3 19
					15 00 00 40 00 00 02 6F 09
					15 00 00 40 00 00 02 C3 19

					// OD setting
					39 00 00 40 00 00 06 F0 55 AA 52 08 08
					39 00 00 40 00 00 05 E0 41 01 01 01
					39 00 00 40 00 00 02 6F 06
					39 00 00 40 00 00 0E E0 80 00 21 32 43 54 65 76 87 98 99 99 99
					39 00 00 40 00 00 0F E1 03 20 04 0D 0E 0F 0F 10 12 14 14 17 1C 20
					39 00 00 40 00 00 0F E2 03 20 04 0A 0C 0E 10 12 17 1A 1E 1F 20 21
					39 00 00 40 00 00 0F E3 00 00 00 00 00 00 00 00 00 00 00 00 00 00
					39 00 00 40 00 00 02 6F 0E
					39 00 00 40 00 00 0F E1 03 16 08 0A 0B 0B 0C 0D 0E 0E 12 14 17 20
					39 00 00 40 00 00 02 6F 0E
					39 00 00 40 00 00 0F E2 03 1C 0A 0F 10 10 11 12 13 13 14 15 17 19
					39 00 00 40 00 00 02 6F 0E
					39 00 00 40 00 00 0F E3 00 00 00 00 00 00 00 00 00 00 00 00 00 00
					39 00 00 40 00 00 02 6F 1C
					39 00 00 40 00 00 0F E1 02 0D 04 0A 0A 0A 0A 0A 0A 0A 0B 0B 0D 0F
					39 00 00 40 00 00 02 6F 1C
					39 00 00 40 00 00 0F E2 02 12 06 06 06 07 08 08 08 08 08 0A 0C 0D
					39 00 00 40 00 00 02 6F 1C
					39 00 00 40 00 00 0F E3 00 00 00 04 04 04 04 04 07 07 08 08 0C 0F
					39 00 00 40 00 00 02 6F 2A
					39 00 00 40 00 00 0F E1 01 0A 04 05 05 06 07 08 08 0A 0B 0B 0E 13
					39 00 00 40 00 00 02 6F 2A
					39 00 00 40 00 00 0F E2 02 12 04 08 08 08 08 08 08 08 0A 0B 0D 11
					39 00 00 40 00 00 02 6F 2A
					39 00 00 40 00 00 0F E3 00 00 00 03 03 03 03 03  03 07 09 0B 0D 12
					39 00 00 40 00 00 02 6F 38
					39 00 00 40 00 00 0F E1 01 08 04 05 05 05 05 05 06 09 0A 0B 0D 11
					39 00 00 40 00 00 02 6F 38
					39 00 00 40 00 00 0F E2 01 0A 04 05 05 05 06 06 06 07 09 0B 0D 10
					39 00 00 40 00 00 02 6F 38
					39 00 00 40 00 00 0F E3 00 00 00 04 04 04 04 04 05 07 08 0A 0D 0F
					39 00 00 40 00 00 02 6F 46
					39 00 00 40 00 00 0F E1 01 06 03 05 05 05 05 05 06 08 09 0B 0C 0F
					39 00 00 40 00 00 02 6F 46
					39 00 00 40 00 00 0F E2 01 06 03 04 04 04 04 04 06 08 09 0A 0C 0F
					39 00 00 40 00 00 02 6F 46
					39 00 00 40 00 00 0F E3 00 00 00 03 03 03 03 03 06 08 09 0A 0C 10
					39 00 00 40 00 00 02 6F 54
					39 00 00 40 00 00 0F E1 01 06 03 04 04 04 04 04 06 08 09 0A 0B 0F
					39 00 00 40 00 00 02 6F 54
					39 00 00 40 00 00 0F E2 01 06 03 04 04 04 04 04 06 07 09 0A 0B 0E
					39 00 00 40 00 00 02 6F 54
					39 00 00 40 00 00 0F E3 00 00 00 02 02 03 03 04 05 07 09 0C 0E 12
					39 00 00 40 00 00 02 6F 62
					39 00 00 40 00 00 0F E1 01 02 02 03 03 04 04 04 06 07 08 0A 0C 0F
					39 00 00 40 00 00 02 6F 62
					39 00 00 40 00 00 0F E2 01 02 02 02 03 03 03 04 05 07 08 09 0A 0E
					39 00 00 40 00 00 02 6F 62
					39 00 00 40 00 00 0F E3 00 00 00 02 02 03 03 04 06 08 0A 0D 0E 12
					39 00 00 40 00 00 02 6F 70
					39 00 00 40 00 00 0F E1 01 02 02 02 03 03 03 04 05 07 09 0C 0D 11
					39 00 00 40 00 00 02 6F 70
					39 00 00 40 00 00 0F E2 01 02 02 02 03 03 03 04 05 07 09 0B 0C 0F
					39 00 00 40 00 00 02 6F 70
					39 00 00 40 00 00 0F E3 00 00 00 02 03 03 03 04 06 08 0B 0C 0C 0F

					//add uir config
					39 00 00 40 00 00 06 F0 55 AA 52 08 00
					15 00 00 40 00 00 02 6F 78
					39 00 00 40 00 00 18 B0 17 00 2A 00 C2 01 DA 03 7C 05 B1 08 80 0B EE 0F FF 05 55 05 56 05 55
					//APL_BLK_R_NUM,APL_BLK_G_NUM,APL_BLK_B_NUM
					15 00 00 40 00 00 02 6F 6F
					39 00 00 40 00 00 07 B0 02 D0 05 A0 02 D0
					//Data Scale Ratio
					39 00 00 40 00 00 06 F0 55 AA 52 08 08
					//DS_LV0_APL0
					39 00 00 40 00 00 17 C1 8E 33 EE 33 33 EE 33 33 EE 33 33 EE 33 33 BE 33 AC 9B AC 0D 0F FF
					//HBM_LV
					15 00 00 40 00 00 02 6F 1D
					39 00 00 40 00 00 03 C1 00 FF
					//APL_L/APL_H
					15 00 00 40 00 00 02 6F 20
					39 00 00 40 00 00 04 C1 0F 29 FF
					//DS_LV0_APL1
					15 00 00 40 00 00 02 6F 23
					39 00 00 40 00 00 15 C1 0E 33 EE 33 33 EE 33 33 EE 33 33 EE 33 33 BE 33 AC 9B AC 0D
					//DS_Lv1_Apl0
					15 00 00 40 00 00 02 6F 37
					39 00 00 40 00 00 15 C1 0F FF FF FF FF FF FF FF FF FF FF FF FF FF DF FF 27 AD 27 33
					//DS_Lv1_Apl1
					15 00 00 40 00 00 02 6F 4B
					39 00 00 40 00 00 15 C1 0E 33 EE 33 33 EE 33 33 EE 33 33 EE 33 33 BE 33 AC 9B AC 0D
					//DS_LV2_APL0
					15 00 00 40 00 00 02 6F 5F
					39 00 00 40 00 00 15 C1 0F FF FF FF FF FF FF FF FF FF FF FF FF FF FF FF FF FF FF FF
					//DS_LV2_APL1
					15 00 00 40 00 00 02 6F 73
					39 00 00 40 00 00 15 C1 0E 33 EE 33 33 EE 33 33 EE 33 33 EE 33 33 BE 33 AC 9B AC 0D
					//DS_DBV_TH
					39 00 00 40 00 00 11 BA 00 01 00 8A 00 8A 01 3C 01 3C 01 9D 01 9D 02 79
					15 00 00 40 00 00 02 6F 10
					39 00 00 40 00 00 11 BA 02 79 03 7D 03 7D 04 93 04 93 06 98 06 98 0A E2
					15 00 00 40 00 00 02 6F 20
					39 00 00 40 00 00 0D BA 0A E2 0D BB 0D BB 0F FE 0F FE 0F FF
					//GIR1.0
					15 00 00 40 00 00 02 6F 07
					15 00 00 00 00 00 02 51 00

					//Sleep out
					15 00 00 00 78 00 02 11 00
					//Display out
					15 00 00 00 00 00 02 29 00
					//scale up on
					39 00 00 40 00 00 05 2A 00 00 04 37
					39 00 00 40 00 00 05 2B 00 00 09 2F
					39 00 00 40 00 00 02 03 10
					39 00 00 40 00 00 02 8F 01
					//OSC Trim
					39 00 00 40 00 00 50 A9 02 01 C3 02 03 02 67 02 01 C3 08 08 67 02 01 C3 0B 0D 3F 51 FE 02 01 C3 0E 0F 3F 25 02 01 C3 10 10 A9 02 01 C3 11 13 3F 51 FE 02 01 C3 14 16 3F 25 A9 02 01 C3 23 25 3F 38 FC 02 01 C3 26 27 3F 2C 02 01 C3 28 28 A8 02 01 C3 29 2B 00 00 00
					//DSC setting lock
					39 00 00 40 00 00 07 A9 02 00 D8 0D 0D 42
					//FPS setting 144Hz
					39 00 00 00 01 00 8F A9 01 00 2F 00 00 00 02 09 BD 00 00 05 02 08 B7 08 0F 02 58 02 58 04 B0 04 B0 02 08 B7 10 1F 07 6C 07 6C 07 08 07 08 0A 28 0A 28 0B B8 0B B8 02 08 B7 20 27 0D AC 0D AC 0C E4 0C E4 02 08 B7 28 2D 0B B8 0B B8 0B B8 01 00 A2 00 20 07 02 01 DD 02 03 05 BE 00 00 00 00 00 00 02 04 B5 02 03 00 0C 00 00 00 00 00 00 01 00 9D 00 00 AA 01 00 8D 02 02 01 01 00 A3 00 0F 81 00 00 00 00 02 09 BD 00 00 04 00 00 00 00 00 01 00 A3 10 11 00 00
				];

				qcom,lm-split = <540 540>;
				qcom,mdss-dsc-slice-height = <16>;
				qcom,mdss-dsc-slice-width = <540>;
			};

		};
	};
};

&soc {
	dsi_panel_AE084_P_3_A0033_dsc_cmd_dvt03 {
		qcom,dsi-display-active;
	};
};

&dsi_panel_AE084_P_3_A0033_dsc_cmd_dvt03 {
	qcom,panel-supply-entries = <&oplus_dsi_panel_custom_pwr_supply>;
	qcom,platform-te-gpio = <&tlmm 86 0>;
	qcom,platform-reset-gpio = <&tlmm 171 0>;
	/* OLED_PMIC_RST */
	oplus,panel-gpio1 = <&pmk8850_gpios 1 0>;
	/* VDDR_SM_1P5_EN */
	oplus,panel-gpio2 = <&pmh0101_gpios 4 0>;

    oplus,panel-reset-position = <0x02>;
	oplus,panel-power-on-sequence = "1", "vddio", "1", "vdd","1", "gpio1", "1", "vci", "1", "gpio2", "10";
	oplus,panel-power-off-sequence = "1", "gpio2", "3", "vci", "3", "gpio1", "3", "vdd", "3", "vddio", "1";

    //enable mipi strength
	oplus,enhance_mipi_strength;

    /* BRIGHTNESS CONFIG */
    qcom,mdss-dsi-bl-pmic-control-type = "bl_ctrl_dcs";
	qcom,bl-update-flag = "delay_until_first_frame";
    qcom,mdss-dsi-bl-inverted-dbv;
    qcom,mdss-dsi-bl-min-level = <138>;
	qcom,mdss-dsi-bl-max-level = <4094>;
	qcom,mdss-brightness-max-level = <4094>;
	oplus,dsi-bl-normal-max-level = <3515>;
	oplus,dsi-brightness-normal-max-level = <3515>;
	oplus,dsi-dc-backlight-threshold = <1960>;
	oplus,dsi-brightness-default-level = <1228>;
	oplus,panel_backlight_check_disable;
	oplus,dsi-bl-limit-normal-min-level = <138>;

    /* ESD CONFIG */
    qcom,esd-check-enabled;
    oplus,esd-check-flag-enabled;
    qcom,mdss-dsi-panel-status-check-mode = "reg_read";
    qcom,mdss-dsi-panel-status-command = [
            06 00 00 00 00 00 01 0A
    ];
    qcom,mdss-dsi-panel-status-command-state = "dsi_lp_mode";
    qcom,mdss-dsi-panel-status-value = <
            0x9C
    >;
    qcom,mdss-dsi-panel-status-read-length = <1>;
    oplus,mdss-dsi-panel-status-match-modes = <0x00000000>;

    /* FACTORY CONFIG */
    oplus,mdss-dsi-vendor-name = "A0033";
    oplus,mdss-dsi-manufacture = "P_3";
	oplus,color_vivid_status;
	oplus,color_srgb_status;
	oplus,color_softiris_status;
	//oplus,color_oplus_calibrate_status;
	oplus,color_dual_brightness_status;
	oplus,color_2nit_status;
	oplus,color_loading_status;
	oplus,color_nature_profession_status;
	oplus,mdss-dsi-panel-type = <0>;

    /* OPLUS FEATURES CONFIG */
	oplus,dsi-serial-number-enabled;
	oplus,dsi-serial-number-switch-page;
	oplus,dsi-serial-number-index= <0>;
	oplus,dsi-serial-number-reg= <0xD7>;
	oplus,dsi-serial-number-read-count= <7>;
	qcom,ulps-enabled;
	qcom,dsi-select-clocks = "pll_byte_clk0", "pll_dsi_clk0";

	oplus,panel-all-timing-switch-frame-delay;

	oplus,vreg_ctrl_flag;
	oplus,dsi-lut-set-enabled;
	oplus,wait-te-config = <0x00000002>;

	/* ofp config */
	oplus,ofp-fp-type = <0x40>;
	oplus,ofp-longrui-aod-config = <0x06>;
	oplus,ofp-need-to-wait-data-before-aod-on;
	oplus,ofp-aod-off-frame-cost = <1>;
	/* adfr config */
	//oplus,adfr-config = <0x0>;  // 0b0000'0000'0101'0001
	//oplus,adfr-test-te-gpio = <&tlmm 85 0>;
	/* just for qsync enable*/
	//qcom,qsync-enable;
	//qcom,mdss-dsi-qsync-min-refresh-rate = <30>;

	/*OPLUS_FEATURE_AP_UIR_DIMMING*/
	/*oplus,apuir-up800nit-ds-list   = <DX1X0   DS1X3   DS2X0>;*/
	/*oplus,apuir-less800nit-ds-list = <DX1X0   DS1X3>;*/
	oplus,apuir-up800nit-ds-list   = <2988   3320   4095>;
	oplus,apuir-less800nit-ds-list = <3635   4095>;

	qcom,mdss-dsi-display-timings {
		//2K
		timing@wqhd_sdc_120 {
			qcom,mdss-dsi-panel-phy-timings = [00 2F 0C 0C 1E 1B 0C 0D 0C 02 04 00 26 11];
			qcom,display-topology = <1 1 1>,<2 2 1>;
			qcom,default-topology-index = <1>;
			qcom,dsi-mode-te-width-us = <220>;
		};
		timing@wqhd_sdc_90 {
			qcom,mdss-dsi-panel-phy-timings = [00 2F 0C 0C 1E 1B 0C 0D 0C 02 04 00 26 11];
			qcom,display-topology = <1 1 1>,<2 2 1>;
			qcom,default-topology-index = <1>;
			qcom,dsi-mode-te-width-us = <3100>;
		};
		timing@wqhd_sdc_60 {
			qcom,mdss-dsi-panel-phy-timings = [00 2F 0C 0C 1E 1B 0C 0D 0C 02 04 00 26 11];
			qcom,display-topology = <1 1 1>,<2 2 1>;
			qcom,default-topology-index = <1>;
			qcom,dsi-mode-te-width-us = <8700>;
		};
		timing@wqhd_sdc_144 {
			qcom,mdss-dsi-panel-phy-timings = [00 2F 0C 0C 1E 1B 0C 0D 0C 02 04 00 26 11];
			qcom,display-topology = <1 1 1>,<2 2 1>;
			qcom,default-topology-index = <1>;
			qcom,dsi-mode-te-width-us = <160>;
		};
		//1080P
		timing@fhd_sdc_120 {
			qcom,mdss-dsi-panel-phy-timings = [00 2F 0C 0B 1E 1B 0C 0B 0C 02 04 00 26 11];
			qcom,display-topology = <1 1 1>,<2 2 1>;
			qcom,default-topology-index = <1>;
			qcom,dsi-mode-te-width-us = <220>;
		};
		timing@fhd_sdc_90 {
			qcom,mdss-dsi-panel-phy-timings = [00 2F 0C 0B 1E 1B 0C 0B 0C 02 04 00 26 11];
			qcom,display-topology = <1 1 1>,<2 2 1>;
			qcom,default-topology-index = <1>;
			qcom,dsi-mode-te-width-us = <3100>;
		};
		timing@fhd_sdc_60 {
			qcom,mdss-dsi-panel-phy-timings = [00 2F 0C 0B 1E 1B 0C 0B 0C 02 04 00 26 11];
			qcom,display-topology = <1 1 1>,<2 2 1>;
			qcom,default-topology-index = <1>;
			qcom,dsi-mode-te-width-us = <8700>;
		};
		timing@fhd_sdc_144 {
			qcom,mdss-dsi-panel-phy-timings = [00 2F 0C 0B 1E 1B 0C 0B 0C 02 04 00 26 11];
			qcom,display-topology = <1 1 1>,<2 2 1>;
			qcom,default-topology-index = <1>;
			qcom,dsi-mode-te-width-us = <160>;
		};
	};
};

&dsi_panel_AE084_P_3_A0033_dsc_cmd_dvt03 {
	qcom,panel_voltage_vddi_name = "vddio";
	qcom,panel_voltage_vddi = <0 1800000 1850000 1950000>;
	qcom,panel_voltage_vddr_name = "vddio";
	qcom,panel_voltage_vddr = <1 1800000 1850000 1950000>;
};

&dsi_panel_AE084_P_3_A0033_dsc_cmd_dvt03{
	/* demura dbv config */

	/* pwm config */
	/*	oplus,pwm-switch-config:
		Bit0: pwm feature enable
		Bit1: pwm mode switch enable, need to config switch cmds
		Bit2: force enabled pwm mode switch cmd, will send mode cmd even dbv threshold cmd feature is configed
		Bit3: pwm dbv threshold pulse switch enable, need to config threshold switch cmds
		Bit4: wait te before sending pwm dbv threshold pulse switch cmd
		Bit5: replace specific cmd to other cmd while in pwm 1pulse mode
		Bit6: sending extend cmd while panel power on accroding to current pwm mode
		Bit7: sending extend cmd while timing switch accroding to current pwm pulse level
		Bit8: sending extend cmd after sending dbv threshold cmd in another thread
		...
		Bit24:support pwm mode0
		Bit25:support pwm mode1
		Bit25:support pwm mode2
	*/
	oplus,pwm-switch-config = <0x01000003>;
	/*	oplus,pwm-switch-mode0-states-info/oplus,pwm-switch-mode1-states-info:
		Specific dbv threshold and pulse info of 2 pwm mode, for pulse, 0 symbols 1pulse,
		1symbols 3pulse and 2 symbols 18pulse. The format should be 1 dbv threshold info with
		2 pwm pulse levels left and right(for example, <2 1087 1> means 18pulse while dbv <= 1087
		and 3pulse while dbv > 1087), or only one pulse level, no threshold.
	*/
	oplus,pwm-switch-mode0-states-info = <0>;
	//oplus,pwm-switch-mode2-states-info = <0>;
	/*	oplus,pwm-cmd-switch-map:
		Specific cmd replace relationship while in switch on(1pulse) mode. It is a string array that
		compose with cmd names, every 2 names combine 1 map. For example, map "'a', 'b'" means replace
		a to b while sending a in switch on mode.
	*/
	//oplus,pwm-cmd-switch-map = "qcom,mdss-dsi-nolp-command", "qcom,mdss-dsi-aod-off-pwm-mode2-command",
	//		"qcom,mdss-dsi-timing-switch-command", "qcom,mdss-dsi-timming-switch-pwm-mode2-command";
};
